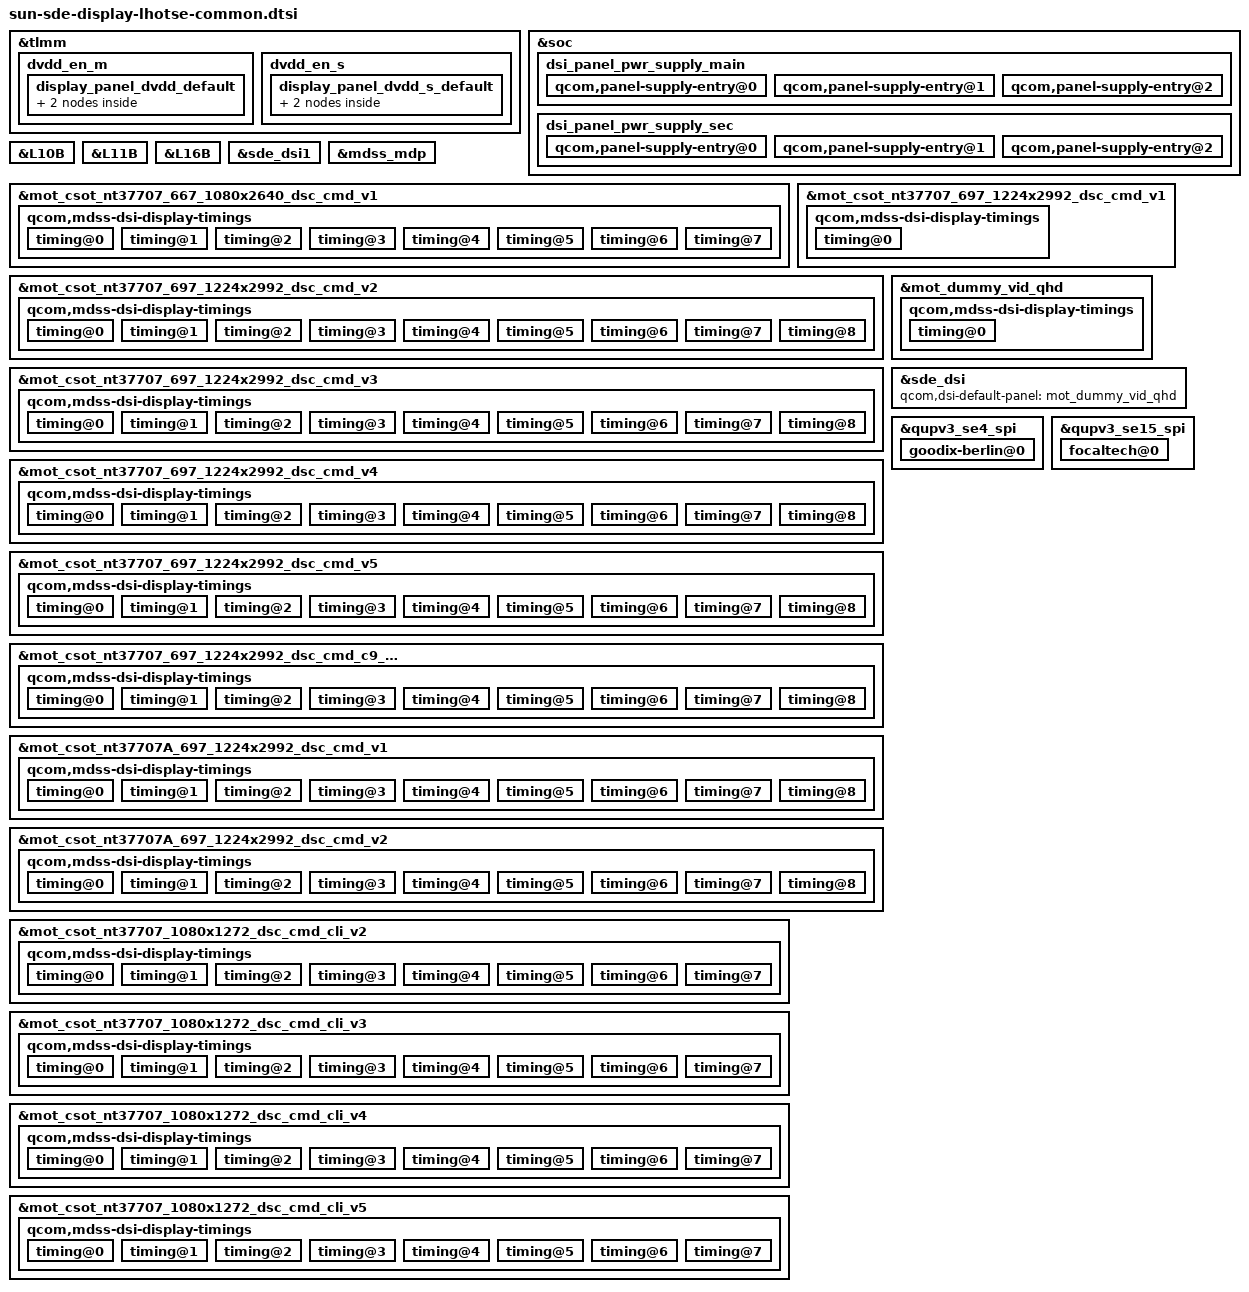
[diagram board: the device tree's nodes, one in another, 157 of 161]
// SPDX-License-Identifier: BSD-3-Clause
/*
 * Copyright (c) 2023-2024, Qualcomm Innovation Center, Inc. All rights reserved.
 */

#include "sun-sde-display.dtsi"
#include "dsi-panel-mot-dummy-qhd-video.dtsi"
#include "dsi-panel-mot-csot-nt37707-667-1080x2640-dsc-cmd-common_v1.dtsi"
#include "dsi-panel-mot-csot-nt37707-697-1224x2992-dsc-cmd-common_v1.dtsi"
#include "dsi-panel-mot-csot-nt37707-697-1224x2992-dsc-cmd-common_v2.dtsi"
#include "dsi-panel-mot-csot-nt37707-697-1224x2992-dsc-cmd-common_v3.dtsi"
#include "dsi-panel-mot-csot-nt37707-697-1224x2992-dsc-cmd-common_v4.dtsi"
#include "dsi-panel-mot-csot-nt37707-697-1224x2992-dsc-cmd-common_v5.dtsi"
#include "dsi-panel-mot-csot-nt37707-697-1224x2992-dsc-cmd-common_c9_v1.dtsi"
#include "dsi-panel-mot-csot-nt37707A-697-1224x2992-dsc-cmd-common_v1.dtsi"
#include "dsi-panel-mot-csot-nt37707A-697-1224x2992-dsc-cmd-common_v2.dtsi"
#include "dsi-panel-mot-csot-nt37707-1080x1272-dsc-cmd-common-cli_v2.dtsi"
#include "dsi-panel-mot-csot-nt37707-1080x1272-dsc-cmd-common-cli_v3.dtsi"
#include "dsi-panel-mot-csot-nt37707-1080x1272-dsc-cmd-common-cli_v4.dtsi"
#include "dsi-panel-mot-csot-nt37707-1080x1272-dsc-cmd-common-cli_v5.dtsi"

&tlmm {
	dvdd_en_m {
		display_panel_dvdd_default: display_panel_dvdd_default { //dvdd 1.23V
			mux {
				pins = "gpio111";
				function = "gpio";
			};

			config {
				pins = "gpio111";
				drive-strength = <2>;   /* 2 mA */
				bias-disable = <0>;   /* no pull */
				output-enable;
			};
		};
	};
	dvdd_en_s {
		display_panel_dvdd_s_default: display_panel_dvdd_s_default {
			mux {
				pins = "gpio60";
				function = "gpio";
			};

			config {
				pins = "gpio60";
				drive-strength = <2>;   /* 2 mA */
				bias-disable = <0>;   /* no pull */
				output-enable;
			};
		};
	};
};

&soc {
	dsi_panel_pwr_supply_main: dsi_panel_pwr_supply_main {
		#address-cells = <1>;
		#size-cells = <0>;

	qcom,panel-supply-entry@0 {
		reg = <0>;
		qcom,supply-name = "vddio";
		qcom,supply-min-voltage = <1800000>;
		qcom,supply-max-voltage = <1800000>;
		qcom,supply-enable-load = <300000>;
		qcom,supply-disable-load = <100>;
		qcom,supply-pre-on-sleep = <0>;
		qcom,supply-post-on-sleep = <1>;
		qcom,supply-pre-off-sleep = <0>;
		qcom,supply-post-off-sleep = <0>;
        };
	qcom,panel-supply-entry@1 {
		reg = <1>;
		qcom,supply-name = "vdd";
		qcom,supply-min-voltage = <1200000>;
		qcom,supply-max-voltage = <1250000>;
		qcom,supply-enable-load = <300000>;
		qcom,supply-disable-load = <100>;
		qcom,supply-pre-on-sleep = <0>;
		qcom,supply-post-on-sleep = <1>;
		qcom,supply-pre-off-sleep = <0>;
		qcom,supply-post-off-sleep = <1>;
        };

        qcom,panel-supply-entry@2 {
		reg = <2>;
		qcom,supply-name = "vci";
		qcom,supply-min-voltage = <3000000>;
		qcom,supply-max-voltage = <3000000>;
		qcom,supply-enable-load = <300000>;
		qcom,supply-disable-load = <0>;
		qcom,supply-pre-on-sleep = <0>;
		qcom,supply-post-on-sleep = <0>;
		qcom,supply-pre-off-sleep = <0>;
		qcom,supply-post-off-sleep = <1>;
        };
	};
	dsi_panel_pwr_supply_sec: dsi_panel_pwr_supply_sec {
		#address-cells = <1>;
		#size-cells = <0>;

	qcom,panel-supply-entry@0 {
		reg = <0>;
		qcom,supply-name = "vddio";
		qcom,supply-min-voltage = <1800000>;
		qcom,supply-max-voltage = <1800000>;
		qcom,supply-enable-load = <300000>;
		qcom,supply-disable-load = <100>;
		qcom,supply-pre-on-sleep = <0>;
		qcom,supply-post-on-sleep = <1>;
		qcom,supply-pre-off-sleep = <0>;
		qcom,supply-post-off-sleep = <0>;
        };
	qcom,panel-supply-entry@1 {
		reg = <1>;
		qcom,supply-name = "vdd";
		qcom,supply-min-voltage = <1250000>;
		qcom,supply-max-voltage = <1250000>;
		qcom,supply-enable-load = <300000>;
		qcom,supply-disable-load = <100>;
		qcom,supply-pre-on-sleep = <0>;
		qcom,supply-post-on-sleep = <1>;
		qcom,supply-pre-off-sleep = <0>;
		qcom,supply-post-off-sleep = <1>;
        };

        qcom,panel-supply-entry@2 {
		reg = <2>;
		qcom,supply-name = "vci";
		qcom,supply-min-voltage = <3000000>;
		qcom,supply-max-voltage = <3000000>;
		qcom,supply-enable-load = <300000>;
		qcom,supply-disable-load = <0>;
		qcom,supply-pre-on-sleep = <0>;
		qcom,supply-post-on-sleep = <0>;
		qcom,supply-pre-off-sleep = <0>;
		qcom,supply-post-off-sleep = <1>;
        };
	};
};

&L10B {
       regulator-min-microvolt = <1800000>;
       regulator-max-microvolt = <1800000>;
       qcom,init-voltage = <1800000>;
};

&L11B {
       regulator-min-microvolt = <1250000>;
       regulator-max-microvolt = <1250000>;
       qcom,init-voltage = <1250000>;
};

&L16B {
       regulator-min-microvolt = <3000000>;
       regulator-max-microvolt = <3000000>;
       qcom,init-voltage = <3000000>;
};

&sde_dsi1 {
	pinctrl-0 = <&sde_dsi1_active &sde_te1_active>;
	pinctrl-1 = <&sde_dsi1_active &sde_te1_active>;
	pinctrl-2 = <&sde_dsi1_suspend &sde_te1_suspend>;
	vddio-supply = <&L10B>;
	vdd-supply = <&L11B>;
	vci-supply = <&L16B>;
};

&mdss_mdp {
	connectors = <&sde_dsi &sde_dsi1 &smmu_sde_unsec &smmu_sde_sec &sde_wb1 &sde_wb2 &sde_cesta>;
};

&mot_csot_nt37707_667_1080x2640_dsc_cmd_v1 {
	qcom,dsi-select-clocks = "pll_byte_clk0", "pll_dsi_clk0";
	qcom,panel-supply-entries = <&dsi_panel_pwr_supply_main>;
	qcom,mdss-dsi-no-panel-on-read-support;
	qcom,mdss-dsi-bl-pmic-control-type = "bl_ctrl_dcs";
	qcom,mdss-dsi-bl-min-level = <420>;
	qcom,mdss-dsi-bl-max-level = <15584>;
	qcom,mdss-dsi-bl-default-level = <8190>;
	qcom,mdss-brightness-max-level = <15584>;
	qcom,platform-reset-gpio = <&tlmm 98 0>;
	qcom,platform-vdd-enable-gpio = <&tlmm 111 0>;
	qcom,bl-dsc-cmd-state = "dsi_hs_mode";
	qcom,mdss-dsi-bl-inverted-dbv;
	qcom,mdss-dsi-bl-is-exponent;

	qcom,mdss-dsi-panel-status-check-mode = "reg_read";
	qcom,mdss-dsi-panel-status-command = [06 01 00 01 00 00 01 0a];
	qcom,mdss-dsi-panel-status-command-state = "dsi_lp_mode";
	qcom,mdss-dsi-panel-status-value = <0x9c>;
	qcom,mdss-dsi-panel-status-read-length = <1>;
	qcom,esd-check-enabled;
	qcom,cellid-read-enabled;
	qcom,mdss-dsi-panel-cellid-read-length = <36>;
	qcom,mdss-dsi-panel-cellid-offset = <13>;
	qcom,mdss-dsi-panel-cellid-command = [
		06 01 00 01 00 00 01 AC];

	qcom,mdss-dsi-panel-hdr-enabled;
	qcom,mdss-dsi-panel-hdr-color-primaries = <15600 16450 34000
	        16000 13250 34500 7500 3000>;
	qcom,mdss-dsi-panel-peak-brightness = <15000000>;
	qcom,mdss-dsi-panel-blackness-level = <1>;

	qcom,apl-enabled;
	qcom,mdss-dsi-panel-APL-THRESHOLD-BL = <15102>;
	qcom,mdss-dsi-panel-APL-FUNC-ID = <0>;
	qcom,mdss-dsi-panel-apl-on-command = [
		39 00 00 00 00 00 03 5F 00 01];
	qcom,mdss-dsi-panel-apl-off-command = [
		39 00 00 00 00 00 03 5F 00 00];
	qcom,is_legacy_panel;
	//qcom,ulps-enabled;
	qcom,mdss-dsi-display-timings {
		timing@0 { //120
			qcom,framerate-group-no-duplicated;
			qcom,framerate-group-120hz-based;
			qcom,partial-update-enabled = "single_roi";
			qcom,panel-roi-alignment = <1080 120 1080 120 1080 120>;
			//qcom,mdss-dsi-panel-clockrate = <800000000>;
			qcom,display-topology = <1 1 1>;
			qcom,default-topology-index = <0>;
			qcom,mdss-dsi-panel-phy-timings = [00 1B 07 06 16 15 07
							07 07 02 04 00 17 0C];
		};
		timing@1 { //90
			qcom,framerate-group-no-duplicated;
			qcom,framerate-group-90hz-based;
			qcom,partial-update-enabled = "single_roi";
			qcom,panel-roi-alignment = <1080 120 1080 120 1080 120>;
			//qcom,mdss-dsi-panel-clockrate = <600000000>;
			qcom,display-topology = <1 1 1>;
			qcom,default-topology-index = <0>;
			qcom,mdss-dsi-panel-phy-timings = [00 16 05 05 14 1F 06
							05 06 02 04 00 13 0A];
		};
		timing@2 { //60
			qcom,framerate-group-no-duplicated;
			qcom,framerate-group-120hz-based;
			qcom,partial-update-enabled = "single_roi";
			qcom,panel-roi-alignment = <1080 120 1080 120 1080 120>;
			qcom,mdss-dsi-panel-clockrate = <500000000>;
			qcom,display-topology = <1 1 1>;
			qcom,default-topology-index = <0>;
			qcom,mdss-dsi-panel-phy-timings = [00 1B 07 06 16 21 07
							07 07 02 04 00 17 0C];
		};
		timing@3 { //30
			qcom,framerate-group-no-duplicated;
			qcom,framerate-group-120hz-based;
			qcom,framerate-group-90hz-based;
			qcom,partial-update-enabled = "single_roi";
			qcom,panel-roi-alignment = <1080 120 1080 120 1080 120>;
			//qcom,mdss-dsi-panel-clockrate = <800000000>;
			qcom,display-topology = <1 1 1>;
			qcom,default-topology-index = <0>;
			qcom,mdss-dsi-panel-phy-timings = [00 1B 07 06 16 21 07
							07 07 02 04 00 17 0C];
		};
		timing@4 { //24
			qcom,framerate-group-no-duplicated;
			qcom,framerate-group-120hz-based;
			qcom,partial-update-enabled = "single_roi";
			qcom,panel-roi-alignment = <1080 120 1080 120 1080 120>;
			//qcom,mdss-dsi-panel-clockrate = <800000000>;
			qcom,display-topology = <1 1 1>;
			qcom,default-topology-index = <0>;
			qcom,mdss-dsi-panel-phy-timings = [00 1B 07 06 16 15 07
							07 07 02 04 00 17 0C];
		};
		timing@5 { //10 independent
			qcom,framerate-group-special-idle-10hz;
			qcom,partial-update-enabled = "single_roi";
			qcom,panel-roi-alignment = <1080 120 1080 120 1080 120>;
			//qcom,mdss-dsi-panel-clockrate = <809000000>;
			qcom,display-topology = <1 1 1>;
			qcom,default-topology-index = <0>;
			qcom,mdss-dsi-panel-phy-timings = [00 1B 07 07 17 15 07
							07 08 02 04 00 18 0C];
		};
		timing@6 { //1 independent
			qcom,framerate-group-special-idle-1hz;
			qcom,partial-update-enabled = "single_roi";
			qcom,panel-roi-alignment = <1080 120 1080 120 1080 120>;
			//qcom,mdss-dsi-panel-clockrate = <809000000>;
			qcom,display-topology = <1 1 1>;
			qcom,default-topology-index = <0>;
			qcom,mdss-dsi-panel-phy-timings = [00 1B 07 07 17 15 07
							07 08 02 04 00 18 0C];
		};
		timing@7 { //165
			qcom,framerate-group-no-duplicated;
			qcom,partial-update-enabled = "single_roi";
			qcom,panel-roi-alignment = <1080 120 1080 120 1080 120>;
			//qcom,mdss-dsi-panel-clockrate = <1100000000>;
			qcom,display-topology = <1 1 1>;
			qcom,default-topology-index = <0>;
			qcom,mdss-dsi-panel-phy-timings = [00 24 0A 0A 1A 19 09
							0A 09 02 04 00 1E 0F];
		};
	};
};

&mot_csot_nt37707_697_1224x2992_dsc_cmd_v1 {
	qcom,dsi-select-clocks = "pll_byte_clk0", "pll_dsi_clk0";
	qcom,panel-supply-entries = <&dsi_panel_pwr_supply_main>;
	qcom,mdss-dsi-no-panel-on-read-support;
	qcom,mdss-dsi-bl-pmic-control-type = "bl_ctrl_dcs";
	qcom,mdss-dsi-bl-min-level = <420>;
	qcom,mdss-dsi-bl-max-level = <15584>;
	qcom,mdss-dsi-bl-default-level = <8190>;
	qcom,mdss-brightness-max-level = <15584>;
	qcom,platform-reset-gpio = <&tlmm 98 0>;
	qcom,platform-vdd-enable-gpio = <&tlmm 111 0>;
	qcom,bl-dsc-cmd-state = "dsi_hs_mode";
	qcom,mdss-dsi-bl-inverted-dbv;
	qcom,mdss-dsi-bl-is-exponent;

	qcom,mdss-dsi-panel-status-check-mode = "reg_read";
	qcom,mdss-dsi-panel-status-command = [06 01 00 01 00 00 01 0a];
	qcom,mdss-dsi-panel-status-command-state = "dsi_lp_mode";
	qcom,mdss-dsi-panel-status-value = <0x9c>;
	qcom,mdss-dsi-panel-status-read-length = <1>;
	qcom,esd-check-enabled;
	qcom,cellid-read-enabled;
	qcom,mdss-dsi-panel-cellid-read-length = <36>;
	qcom,mdss-dsi-panel-cellid-offset = <13>;
	qcom,mdss-dsi-panel-cellid-command = [
		06 01 00 01 00 00 01 AC];

	qcom,mdss-dsi-panel-hdr-enabled;
	qcom,mdss-dsi-panel-hdr-color-primaries = <15600 16450 34000
	        16000 13250 34500 7500 3000>;
	qcom,mdss-dsi-panel-peak-brightness = <20000000>;
	qcom,mdss-dsi-panel-blackness-level = <1>;

	//qcom,apl-enabled;
	qcom,mdss-dsi-panel-APL-THRESHOLD-BL = <15102>;
	qcom,mdss-dsi-panel-APL-FUNC-ID = <0>;
	qcom,mdss-dsi-panel-apl-on-command = [
		39 00 00 00 00 00 03 5F 00 01];
	qcom,mdss-dsi-panel-apl-off-command = [
		39 00 00 00 00 00 03 5F 00 00];
	qcom,is_legacy_panel;
	//qcom,ulps-enabled;
	qcom,mdss-dsi-display-timings {
		timing@0 { //120
			qcom,framerate-group-no-duplicated;
			qcom,framerate-group-120hz-based;
			qcom,partial-update-enabled = "single_roi";
			qcom,panel-roi-alignment = <1224 160 1224 160 1224 160>;
			//qcom,mdss-dsi-panel-clockrate = <800000000>;
			qcom,display-topology = <2 2 1>;
			qcom,default-topology-index = <0>;
			qcom,mdss-dsi-panel-phy-timings = [00 2B 0C 0C 1C 1A 0C
							0C 0B 02 04 00 24 10];
		};
		/*timing@1 { //90
			qcom,framerate-group-no-duplicated;
			qcom,framerate-group-90hz-based;
			qcom,partial-update-enabled = "single_roi";
			qcom,panel-roi-alignment = <1224 120 1224 120 1224 120>;
			//qcom,mdss-dsi-panel-clockrate = <600000000>;
			qcom,display-topology = <2 2 1>;
			qcom,default-topology-index = <0>;
			qcom,mdss-dsi-panel-phy-timings = [00 2B 0C 0C 1C 1A 0C
							0C 0B 02 04 00 24 10];
		};
		timing@2 { //165 independent
			qcom,framerate-group-special-idle-1hz;
			qcom,partial-update-enabled = "single_roi";
			qcom,panel-roi-alignment = <1224 120 1224 120 1224 120>;
			//qcom,mdss-dsi-panel-clockrate = <809000000>;
			qcom,display-topology = <2 2 1>;
			qcom,default-topology-index = <0>;
			qcom,mdss-dsi-panel-phy-timings = [00 2B 0C 0C 1C 1A 0C
							0C 0B 02 04 00 24 10];
		};*/
	};
};

&mot_csot_nt37707_697_1224x2992_dsc_cmd_v2 {
	qcom,dsi-select-clocks = "pll_byte_clk0", "pll_dsi_clk0";
	qcom,panel-supply-entries = <&dsi_panel_pwr_supply_main>;
	qcom,mdss-dsi-no-panel-on-read-support;
	qcom,mdss-dsi-bl-pmic-control-type = "bl_ctrl_dcs";
	qcom,mdss-dsi-bl-min-level = <420>;
	qcom,mdss-dsi-bl-max-level = <15584>;
	qcom,mdss-dsi-bl-default-level = <8190>;
	qcom,mdss-brightness-max-level = <15584>;
	qcom,platform-reset-gpio = <&tlmm 98 0>;
	qcom,platform-vdd-enable-gpio = <&tlmm 111 0>;
	qcom,bl-dsc-cmd-state = "dsi_hs_mode";
	qcom,mdss-dsi-bl-inverted-dbv;
	qcom,mdss-dsi-bl-is-exponent;

	qcom,mdss-dsi-panel-status-check-mode = "reg_read";
	qcom,mdss-dsi-panel-status-command = [06 01 00 01 00 00 01 0a];
	qcom,mdss-dsi-panel-status-command-state = "dsi_lp_mode";
	qcom,mdss-dsi-panel-status-value = <0x9c>;
	qcom,mdss-dsi-panel-status-read-length = <1>;
	qcom,esd-check-enabled;
	qcom,cellid-read-enabled;
	qcom,mdss-dsi-panel-cellid-read-length = <36>;
	qcom,mdss-dsi-panel-cellid-offset = <13>;
	qcom,mdss-dsi-panel-cellid-command = [
		06 01 00 01 00 00 01 AC];

	qcom,mdss-dsi-panel-hdr-enabled;
	qcom,mdss-dsi-panel-hdr-color-primaries = <15600 16450 34000
	        16000 13250 34500 7500 3000>;
	qcom,mdss-dsi-panel-peak-brightness = <20000000>;
	qcom,mdss-dsi-panel-blackness-level = <1>;

	//qcom,apl-enabled;
	qcom,mdss-dsi-panel-APL-THRESHOLD-BL = <15102>;
	qcom,mdss-dsi-panel-APL-FUNC-ID = <0>;
	qcom,mdss-dsi-panel-apl-on-command = [
		39 00 00 00 00 00 03 5F 00 01];
	qcom,mdss-dsi-panel-apl-off-command = [
		39 00 00 00 00 00 03 5F 00 00];
	qcom,partition-refreshrate-enabled;
	qcom,mdss-dsi-panel-boundaryLine-reg-count = <6>;
	//qcom,ulps-enabled;
	qcom,is_legacy_panel;
	qcom,mdss-dsi-hbm-off-command = [
		39 00 00 40 00 00 03 5F 00 00
		39 00 00 00 00 00 03 51 2C 50
	];
	qcom,mdss-dsi-hbm-off-command-state = "dsi_hs_mode";
	qcom,mdss-dsi-hbm-on-command = [
		39 00 00 40 00 00 03 5F 00 01
		39 00 00 00 00 00 03 51 3F FC
	];
	qcom,mdss-dsi-hbm-on-command-state = "dsi_hs_mode";
	qcom,mdss-dsi-display-timings {
		timing@0 { //120
			qcom,framerate-group-no-duplicated;
			qcom,framerate-group-120hz-based;
			qcom,partial-update-enabled = "single_roi";
			qcom,panel-roi-alignment = <1224 160 1224 160 1224 160>;
			//qcom,mdss-dsi-panel-clockrate = <1036000000>;
			qcom,display-topology = <2 2 1>;
			qcom,default-topology-index = <0>;
			qcom,mdss-dsi-panel-phy-timings = [00 22 09 09 19 18 09
							09 09 02 04 00 1D 0E];
		};
		timing@1 { //90
			qcom,framerate-group-no-duplicated;
			qcom,framerate-group-90hz-based;
			qcom,partial-update-enabled = "single_roi";
			qcom,panel-roi-alignment = <1224 160 1224 160 1224 160>;
			//qcom,mdss-dsi-panel-clockrate = <777000000>;
			qcom,display-topology = <2 2 1>;
			qcom,default-topology-index = <0>;
			qcom,mdss-dsi-panel-phy-timings = [00 1B 07 06 16 21 07
							07 07 02 04 00 17 0C];
		};
		timing@2 { //60
			qcom,framerate-group-no-duplicated;
			qcom,framerate-group-120hz-based;
			qcom,partial-update-enabled = "single_roi";
			qcom,panel-roi-alignment = <1224 160 1224 160 1224 160>;
			//qcom,mdss-dsi-panel-clockrate = <518000000>;
			qcom,display-topology = <2 2 1>;
			qcom,default-topology-index = <0>;
			qcom,mdss-dsi-panel-phy-timings = [00 13 05 04 13 1E 05
							05 06 02 04 00 12 0A];
		};
		timing@3 { //30
			qcom,framerate-group-no-duplicated;
			qcom,framerate-group-120hz-based;
			qcom,partial-update-enabled = "single_roi";
			qcom,panel-roi-alignment = <1224 160 1224 160 1224 160>;
			//qcom,mdss-dsi-panel-clockrate = <1036000000>;
			qcom,display-topology = <2 2 1>;
			qcom,default-topology-index = <0>;
			qcom,mdss-dsi-panel-phy-timings = [00 22 09 09 19 18 09
							09 09 02 04 00 1D 0E];
		};
		timing@4 { //24
			qcom,framerate-group-no-duplicated;
			qcom,framerate-group-120hz-based;
			qcom,partial-update-enabled = "single_roi";
			qcom,panel-roi-alignment = <1224 160 1224 160 1224 160>;
			//qcom,mdss-dsi-panel-clockrate = <1036000000>;
			qcom,display-topology = <2 2 1>;
			qcom,default-topology-index = <0>;
			qcom,mdss-dsi-panel-phy-timings = [00 22 09 09 19 18 09
							09 09 02 04 00 1D 0E];
		};
		timing@5 { //10 independent
			qcom,framerate-group-special-idle-10hz;
			qcom,partial-update-enabled = "single_roi";
			qcom,panel-roi-alignment = <1224 160 1224 160 1224 160>;
			//qcom,mdss-dsi-panel-clockrate = <1036000000>;
			qcom,display-topology = <2 2 1>;
			qcom,default-topology-index = <0>;
			qcom,mdss-dsi-panel-phy-timings = [00 22 09 09 19 18 09
							09 09 02 04 00 1D 0E];
		};
		timing@6 { //1 independent
			qcom,framerate-group-special-idle-1hz;
			qcom,partial-update-enabled = "single_roi";
			qcom,panel-roi-alignment = <1224 160 1224 160 1224 160>;
			//qcom,mdss-dsi-panel-clockrate = <1036000000>;
			qcom,display-topology = <2 2 1>;
			qcom,default-topology-index = <0>;
			qcom,mdss-dsi-panel-phy-timings = [00 22 09 09 19 18 09
							09 09 02 04 00 1D 0E];
		};
		timing@7 { //165
			qcom,framerate-group-no-duplicated;
			qcom,partial-update-enabled = "single_roi";
			qcom,panel-roi-alignment = <1224 160 1224 160 1224 160>;
			//qcom,mdss-dsi-panel-clockrate = <1424000000>;
			qcom,display-topology = <2 2 1>;
			qcom,default-topology-index = <0>;
			qcom,mdss-dsi-panel-phy-timings = [00 2E 0C 0C 1D 1B 0C
							0D 0B 02 04 00 25 11];
		};
		/*timing@8 { //10-120-10 independent
			qcom,framerate-group-partition-refreshrate;
			qcom,partial-update-enabled = "single_roi";
			qcom,panel-roi-alignment = <1224 160 1224 160 1224 160>;
			//qcom,mdss-dsi-panel-clockrate = <1036000000>;
			qcom,display-topology = <2 2 1>;
			qcom,default-topology-index = <0>;
			qcom,mdss-dsi-panel-phy-timings = [00 22 09 09 19 18 09
							09 09 02 04 00 1D 0E];
		};*/
		timing@8 { //10-60-10 independent
			qcom,framerate-group-partition-refreshrate;
			qcom,partial-update-enabled = "single_roi";
			qcom,panel-roi-alignment = <1224 160 1224 160 1224 160>;
			qcom,mdss-dsi-panel-clockrate = <1036000000>;
			qcom,display-topology = <2 2 1>;
			qcom,default-topology-index = <0>;
			qcom,mdss-dsi-panel-phy-timings = [00 22 09 09 19 18 09
							09 09 02 04 00 1D 0E];
		};
	};
};

&mot_csot_nt37707_697_1224x2992_dsc_cmd_v3 {
	qcom,dsi-select-clocks = "pll_byte_clk0", "pll_dsi_clk0";
	qcom,panel-supply-entries = <&dsi_panel_pwr_supply_main>;
	qcom,mdss-dsi-no-panel-on-read-support;
	qcom,mdss-dsi-bl-pmic-control-type = "bl_ctrl_dcs";
	qcom,mdss-dsi-bl-min-level = <420>;
	qcom,mdss-dsi-bl-max-level = <15584>;
	qcom,mdss-dsi-bl-default-level = <8190>;
	qcom,mdss-brightness-max-level = <15584>;
	qcom,platform-reset-gpio = <&tlmm 98 0>;
	qcom,platform-vdd-enable-gpio = <&tlmm 111 0>;
	qcom,bl-dsc-cmd-state = "dsi_hs_mode";
	qcom,mdss-dsi-bl-inverted-dbv;
	qcom,mdss-dsi-bl-is-exponent;

	qcom,mdss-dsi-panel-status-check-mode = "reg_read";
	qcom,mdss-dsi-panel-status-command = [06 01 00 01 00 00 01 0a];
	qcom,mdss-dsi-panel-status-command-state = "dsi_lp_mode";
	qcom,mdss-dsi-panel-status-value = <0x9c>;
	qcom,mdss-dsi-panel-status-read-length = <1>;
	qcom,esd-check-enabled;
	qcom,cellid-read-enabled;
	qcom,mdss-dsi-panel-cellid-read-length = <36>;
	qcom,mdss-dsi-panel-cellid-offset = <13>;
	qcom,mdss-dsi-panel-cellid-command = [
		06 01 00 01 00 00 01 AC];

	qcom,mdss-dsi-panel-hdr-enabled;
	qcom,mdss-dsi-panel-hdr-color-primaries = <15600 16450 34000
	        16000 13250 34500 7500 3000>;
	qcom,mdss-dsi-panel-peak-brightness = <20000000>;
	qcom,mdss-dsi-panel-blackness-level = <1>;
	qcom,is_legacy_panel;
	//qcom,apl-enabled;
	qcom,mdss-dsi-panel-APL-THRESHOLD-BL = <15102>;
	qcom,mdss-dsi-panel-APL-FUNC-ID = <0>;
	qcom,mdss-dsi-panel-apl-on-command = [
		39 00 00 00 00 00 03 5F 00 01];
	qcom,mdss-dsi-panel-apl-off-command = [
		39 00 00 00 00 00 03 5F 00 00];
	qcom,partition-refreshrate-enabled;
	qcom,mdss-dsi-panel-boundaryLine-reg-count = <6>;
	//qcom,ulps-enabled;
	qcom,mdss-dsi-hbm-off-command = [
		39 00 00 40 00 00 03 5F 00 00
		39 00 00 00 00 00 03 51 2C 50
	];
	qcom,mdss-dsi-hbm-off-command-state = "dsi_hs_mode";
	qcom,mdss-dsi-hbm-on-command = [
		39 00 00 40 00 00 03 5F 00 01
		39 00 00 00 00 00 03 51 3F FC
	];
	qcom,mdss-dsi-hbm-on-command-state = "dsi_hs_mode";
	qcom,mdss-dsi-display-timings {
		timing@0 { //120
			qcom,framerate-group-no-duplicated;
			qcom,framerate-group-120hz-based;
			qcom,partial-update-enabled = "single_roi";
			qcom,panel-roi-alignment = <1224 160 1224 160 1224 160>;
			qcom,mdss-dsi-panel-clockrate = <1036000000>;
			qcom,display-topology = <2 2 1>;
			qcom,default-topology-index = <0>;
			qcom,mdss-dsi-panel-phy-timings = [00 22 09 09 19 18 09
							09 09 02 04 00 1D 0E];
		};
		timing@1 { //90
			qcom,framerate-group-no-duplicated;
			qcom,framerate-group-90hz-based;
			qcom,partial-update-enabled = "single_roi";
			qcom,panel-roi-alignment = <1224 160 1224 160 1224 160>;
			qcom,mdss-dsi-panel-clockrate = <777000000>;
			qcom,display-topology = <2 2 1>;
			qcom,default-topology-index = <0>;
			qcom,mdss-dsi-panel-phy-timings = [00 1B 07 06 16 21 07
							07 07 02 04 00 17 0C];
		};
		timing@2 { //60
			qcom,framerate-group-no-duplicated;
			qcom,framerate-group-120hz-based;
			qcom,partial-update-enabled = "single_roi";
			qcom,panel-roi-alignment = <1224 160 1224 160 1224 160>;
			qcom,mdss-dsi-panel-clockrate = <518000000>;
			qcom,display-topology = <2 2 1>;
			qcom,default-topology-index = <0>;
			qcom,mdss-dsi-panel-phy-timings = [00 13 05 04 13 1E 05
							05 06 02 04 00 12 0A];
		};
		timing@3 { //30
			qcom,framerate-group-no-duplicated;
			qcom,framerate-group-120hz-based;
			qcom,partial-update-enabled = "single_roi";
			qcom,panel-roi-alignment = <1224 160 1224 160 1224 160>;
			qcom,mdss-dsi-panel-clockrate = <1036000000>;
			qcom,display-topology = <2 2 1>;
			qcom,default-topology-index = <0>;
			qcom,mdss-dsi-panel-phy-timings = [00 22 09 09 19 18 09
							09 09 02 04 00 1D 0E];
		};
		timing@4 { //24
			qcom,framerate-group-no-duplicated;
			qcom,framerate-group-120hz-based;
			qcom,partial-update-enabled = "single_roi";
			qcom,panel-roi-alignment = <1224 160 1224 160 1224 160>;
			qcom,mdss-dsi-panel-clockrate = <1036000000>;
			qcom,display-topology = <2 2 1>;
			qcom,default-topology-index = <0>;
			qcom,mdss-dsi-panel-phy-timings = [00 22 09 09 19 18 09
							09 09 02 04 00 1D 0E];
		};
		timing@5 { //10 independent
			qcom,framerate-group-special-idle-10hz;
			qcom,partial-update-enabled = "single_roi";
			qcom,panel-roi-alignment = <1224 160 1224 160 1224 160>;
			qcom,mdss-dsi-panel-clockrate = <1036000000>;
			qcom,display-topology = <2 2 1>;
			qcom,default-topology-index = <0>;
			qcom,mdss-dsi-panel-phy-timings = [00 22 09 09 19 18 09
							09 09 02 04 00 1D 0E];
		};
		timing@6 { //1 independent
			qcom,framerate-group-special-idle-1hz;
			qcom,partial-update-enabled = "single_roi";
			qcom,panel-roi-alignment = <1224 160 1224 160 1224 160>;
			qcom,mdss-dsi-panel-clockrate = <1036000000>;
			qcom,display-topology = <2 2 1>;
			qcom,default-topology-index = <0>;
			qcom,mdss-dsi-panel-phy-timings = [00 22 09 09 19 18 09
							09 09 02 04 00 1D 0E];
		};
		timing@7 { //165
			qcom,framerate-group-no-duplicated;
			qcom,partial-update-enabled = "single_roi";
			qcom,panel-roi-alignment = <1224 160 1224 160 1224 160>;
			qcom,mdss-dsi-panel-clockrate = <1424000000>;
			qcom,display-topology = <2 2 1>;
			qcom,default-topology-index = <0>;
			qcom,mdss-dsi-panel-phy-timings = [00 2E 0C 0C 1D 1B 0C
							0D 0B 02 04 00 25 11];
		};
		/*timing@8 { //10-120-10 independent
			qcom,framerate-group-partition-refreshrate;
			qcom,partial-update-enabled = "single_roi";
			qcom,panel-roi-alignment = <1224 160 1224 160 1224 160>;
			qcom,mdss-dsi-panel-clockrate = <1036000000>;
			qcom,display-topology = <2 2 1>;
			qcom,default-topology-index = <0>;
			qcom,mdss-dsi-panel-phy-timings = [00 22 09 09 19 18 09
							09 09 02 04 00 1D 0E];
		};*/
		timing@8 { //10-60-10 independent
			qcom,framerate-group-partition-refreshrate;
			qcom,partial-update-enabled = "single_roi";
			qcom,panel-roi-alignment = <1224 160 1224 160 1224 160>;
			qcom,mdss-dsi-panel-clockrate = <1036000000>;
			qcom,display-topology = <2 2 1>;
			qcom,default-topology-index = <0>;
			qcom,mdss-dsi-panel-phy-timings = [00 22 09 09 19 18 09
							09 09 02 04 00 1D 0E];
		};
	};
};

&mot_csot_nt37707_697_1224x2992_dsc_cmd_v4 {
	qcom,dsi-select-clocks = "pll_byte_clk0", "pll_dsi_clk0";
	qcom,panel-supply-entries = <&dsi_panel_pwr_supply_main>;
	qcom,mdss-dsi-no-panel-on-read-support;
	qcom,mdss-dsi-bl-pmic-control-type = "bl_ctrl_dcs";
	qcom,mdss-dsi-bl-min-level = <420>;
	qcom,mdss-dsi-bl-max-level = <15584>;
	qcom,mdss-dsi-bl-default-level = <8190>;
	qcom,mdss-brightness-max-level = <15584>;
	qcom,platform-reset-gpio = <&tlmm 98 0>;
	qcom,platform-vdd-enable-gpio = <&tlmm 111 0>;
	qcom,bl-dsc-cmd-state = "dsi_hs_mode";
	qcom,mdss-dsi-bl-inverted-dbv;
	qcom,mdss-dsi-bl-is-exponent;

	qcom,mdss-dsi-panel-status-check-mode = "reg_read";
	qcom,mdss-dsi-panel-status-command = [06 01 00 01 00 00 01 0a];
	qcom,mdss-dsi-panel-status-command-state = "dsi_lp_mode";
	qcom,mdss-dsi-panel-status-value = <0x9c>;
	qcom,mdss-dsi-panel-status-read-length = <1>;
	qcom,esd-check-enabled;
	qcom,cellid-read-enabled;
	qcom,mdss-dsi-panel-cellid-read-length = <36>;
	qcom,mdss-dsi-panel-cellid-offset = <13>;
	qcom,mdss-dsi-panel-cellid-command = [
		06 01 00 01 00 00 01 AC];

	qcom,mdss-dsi-panel-hdr-enabled;
	qcom,mdss-dsi-panel-hdr-color-primaries = <15600 16450 34000
	        16000 13250 34500 7500 3000>;
	qcom,mdss-dsi-panel-peak-brightness = <20000000>;
	qcom,mdss-dsi-panel-blackness-level = <1>;
	qcom,is_legacy_panel;
	qcom,apl-enabled;
	qcom,mdss-dsi-panel-APL-THRESHOLD-BL = <15102>;
	qcom,mdss-dsi-panel-APL-FUNC-ID = <0>;
	qcom,mdss-dsi-panel-apl-on-command = [
		39 00 00 00 00 00 03 5F 00 01];
	qcom,mdss-dsi-panel-apl-off-command = [
		39 00 00 00 00 00 03 5F 00 00];
	qcom,partition-refreshrate-enabled;
	qcom,mdss-dsi-panel-boundaryLine-reg-count = <6>;
	//qcom,ulps-enabled;
	qcom,mdss-dsi-hbm-off-command = [
		39 00 00 40 00 00 03 5F 00 00
		39 00 00 00 00 00 03 51 2C 50
	];
	qcom,mdss-dsi-hbm-off-command-state = "dsi_hs_mode";
	qcom,mdss-dsi-hbm-on-command = [
		39 00 00 40 00 00 03 5F 00 01
		39 00 00 00 00 00 03 51 3F FC
	];
	qcom,mdss-dsi-hbm-on-command-state = "dsi_hs_mode";
	qcom,mdss-dsi-display-timings {
		timing@0 { //120
			qcom,framerate-group-no-duplicated;
			qcom,framerate-group-120hz-based;
			qcom,partial-update-enabled = "single_roi";
			qcom,panel-roi-alignment = <1224 160 1224 160 1224 160>;
			qcom,mdss-dsi-panel-clockrate = <1036000000>;
			qcom,display-topology = <2 2 1>;
			qcom,default-topology-index = <0>;
			qcom,mdss-dsi-panel-phy-timings = [00 22 09 09 19 18 09
							09 09 02 04 00 1D 0E];
		};
		timing@1 { //90
			qcom,framerate-group-no-duplicated;
			qcom,framerate-group-90hz-based;
			qcom,partial-update-enabled = "single_roi";
			qcom,panel-roi-alignment = <1224 160 1224 160 1224 160>;
			qcom,mdss-dsi-panel-clockrate = <777000000>;
			qcom,display-topology = <2 2 1>;
			qcom,default-topology-index = <0>;
			qcom,mdss-dsi-panel-phy-timings = [00 1B 07 06 16 21 07
							07 07 02 04 00 17 0C];
		};
		timing@2 { //60
			qcom,framerate-group-no-duplicated;
			qcom,framerate-group-120hz-based;
			qcom,partial-update-enabled = "single_roi";
			qcom,panel-roi-alignment = <1224 160 1224 160 1224 160>;
			qcom,mdss-dsi-panel-clockrate = <518000000>;
			qcom,display-topology = <2 2 1>;
			qcom,default-topology-index = <0>;
			qcom,mdss-dsi-panel-phy-timings = [00 13 05 04 13 1E 05
							05 06 02 04 00 12 0A];
		};
		timing@3 { //30
			qcom,framerate-group-no-duplicated;
			qcom,framerate-group-120hz-based;
			qcom,partial-update-enabled = "single_roi";
			qcom,panel-roi-alignment = <1224 160 1224 160 1224 160>;
			qcom,mdss-dsi-panel-clockrate = <1036000000>;
			qcom,display-topology = <2 2 1>;
			qcom,default-topology-index = <0>;
			qcom,mdss-dsi-panel-phy-timings = [00 22 09 09 19 18 09
							09 09 02 04 00 1D 0E];
		};
		timing@4 { //24
			qcom,framerate-group-no-duplicated;
			qcom,framerate-group-120hz-based;
			qcom,partial-update-enabled = "single_roi";
			qcom,panel-roi-alignment = <1224 160 1224 160 1224 160>;
			qcom,mdss-dsi-panel-clockrate = <1036000000>;
			qcom,display-topology = <2 2 1>;
			qcom,default-topology-index = <0>;
			qcom,mdss-dsi-panel-phy-timings = [00 22 09 09 19 18 09
							09 09 02 04 00 1D 0E];
		};
		timing@5 { //10 independent
			qcom,framerate-group-special-idle-10hz;
			qcom,partial-update-enabled = "single_roi";
			qcom,panel-roi-alignment = <1224 160 1224 160 1224 160>;
			qcom,mdss-dsi-panel-clockrate = <1036000000>;
			qcom,display-topology = <2 2 1>;
			qcom,default-topology-index = <0>;
			qcom,mdss-dsi-panel-phy-timings = [00 22 09 09 19 18 09
							09 09 02 04 00 1D 0E];
		};
		timing@6 { //1 independent
			qcom,framerate-group-special-idle-1hz;
			qcom,partial-update-enabled = "single_roi";
			qcom,panel-roi-alignment = <1224 160 1224 160 1224 160>;
			qcom,mdss-dsi-panel-clockrate = <1036000000>;
			qcom,display-topology = <2 2 1>;
			qcom,default-topology-index = <0>;
			qcom,mdss-dsi-panel-phy-timings = [00 22 09 09 19 18 09
							09 09 02 04 00 1D 0E];
		};
		timing@7 { //165
			qcom,framerate-group-no-duplicated;
			qcom,partial-update-enabled = "single_roi";
			qcom,panel-roi-alignment = <1224 160 1224 160 1224 160>;
			qcom,mdss-dsi-panel-clockrate = <1424000000>;
			qcom,display-topology = <2 2 1>;
			qcom,default-topology-index = <0>;
			qcom,mdss-dsi-panel-phy-timings = [00 2E 0C 0C 1D 1B 0C
							0D 0B 02 04 00 25 11];
		};
		/*timing@8 { //10-120-10 independent
			qcom,framerate-group-partition-refreshrate;
			qcom,partial-update-enabled = "single_roi";
			qcom,panel-roi-alignment = <1224 160 1224 160 1224 160>;
			qcom,mdss-dsi-panel-clockrate = <1036000000>;
			qcom,display-topology = <2 2 1>;
			qcom,default-topology-index = <0>;
			qcom,mdss-dsi-panel-phy-timings = [00 22 09 09 19 18 09
							09 09 02 04 00 1D 0E];
		};*/
		timing@8 { //10-60-10 independent
			qcom,framerate-group-partition-refreshrate;
			qcom,partial-update-enabled = "single_roi";
			qcom,panel-roi-alignment = <1224 160 1224 160 1224 160>;
			qcom,mdss-dsi-panel-clockrate = <1036000000>;
			qcom,display-topology = <2 2 1>;
			qcom,default-topology-index = <0>;
			qcom,mdss-dsi-panel-phy-timings = [00 22 09 09 19 18 09
							09 09 02 04 00 1D 0E];
		};
	};
};

&mot_csot_nt37707_697_1224x2992_dsc_cmd_v5 {
	qcom,dsi-select-clocks = "pll_byte_clk0", "pll_dsi_clk0";
	qcom,panel-supply-entries = <&dsi_panel_pwr_supply_main>;
	qcom,mdss-dsi-no-panel-on-read-support;
	qcom,mdss-dsi-bl-pmic-control-type = "bl_ctrl_dcs";
	qcom,mdss-dsi-bl-min-level = <420>;
	qcom,mdss-dsi-bl-max-level = <15584>;
	qcom,mdss-dsi-bl-default-level = <8190>;
	qcom,mdss-brightness-max-level = <15584>;
	qcom,platform-reset-gpio = <&tlmm 98 0>;
	qcom,platform-vdd-enable-gpio = <&tlmm 111 0>;
	qcom,bl-dsc-cmd-state = "dsi_hs_mode";
	qcom,mdss-dsi-bl-inverted-dbv;
	qcom,mdss-dsi-bl-is-exponent;

	qcom,mdss-dsi-panel-status-check-mode = "reg_read";
	qcom,mdss-dsi-panel-status-command = [06 01 00 01 00 00 01 0a];
	qcom,mdss-dsi-panel-status-command-state = "dsi_lp_mode";
	qcom,mdss-dsi-panel-status-value = <0x9c>;
	qcom,mdss-dsi-panel-status-read-length = <1>;
	qcom,esd-check-enabled;
	qcom,cellid-read-enabled;
	qcom,mdss-dsi-panel-cellid-read-length = <36>;
	qcom,mdss-dsi-panel-cellid-offset = <13>;
	qcom,mdss-dsi-panel-cellid-command = [
		06 01 00 01 00 00 01 AC];

	qcom,mdss-dsi-panel-hdr-enabled;
	qcom,mdss-dsi-panel-hdr-color-primaries = <15600 16450 34000
	        16000 13250 34500 7500 3000>;
	qcom,mdss-dsi-panel-peak-brightness = <20000000>;
	qcom,mdss-dsi-panel-blackness-level = <1>;
	qcom,is_legacy_panel;
	qcom,apl-enabled;
	qcom,mdss-dsi-panel-APL-THRESHOLD-BL = <15102>;
	qcom,mdss-dsi-panel-APL-FUNC-ID = <0>;
	qcom,mdss-dsi-panel-apl-on-command = [
		39 00 00 00 00 00 03 5F 00 01];
	qcom,mdss-dsi-panel-apl-off-command = [
		39 00 00 00 00 00 03 5F 00 00];
	qcom,partition-refreshrate-enabled;
	qcom,mdss-dsi-panel-boundaryLine-reg-count = <6>;
	//qcom,ulps-enabled;
	qcom,mdss-dsi-hbm-off-command = [
		39 00 00 40 00 00 03 5F 00 00
		39 00 00 00 00 00 03 51 2C 50
	];
	qcom,mdss-dsi-hbm-off-command-state = "dsi_hs_mode";
	qcom,mdss-dsi-hbm-on-command = [
		39 00 00 40 00 00 03 5F 00 01
		39 00 00 00 00 00 03 51 3F FC
	];
	qcom,mdss-dsi-hbm-on-command-state = "dsi_hs_mode";
	qcom,mdss-dsi-display-timings {
		timing@0 { //120
			qcom,framerate-group-no-duplicated;
			qcom,framerate-group-120hz-based;
			qcom,partial-update-enabled = "single_roi";
			qcom,panel-roi-alignment = <1224 160 1224 160 1224 160>;
			qcom,mdss-dsi-panel-clockrate = <1036000000>;
			qcom,display-topology = <2 2 1>;
			qcom,default-topology-index = <0>;
			qcom,mdss-dsi-panel-phy-timings = [00 22 09 09 19 18 09
							09 09 02 04 00 1D 0E];
		};
		timing@1 { //90
			qcom,framerate-group-no-duplicated;
			qcom,framerate-group-90hz-based;
			qcom,partial-update-enabled = "single_roi";
			qcom,panel-roi-alignment = <1224 160 1224 160 1224 160>;
			qcom,mdss-dsi-panel-clockrate = <777000000>;
			qcom,display-topology = <2 2 1>;
			qcom,default-topology-index = <0>;
			qcom,mdss-dsi-panel-phy-timings = [00 1B 07 06 16 21 07
							07 07 02 04 00 17 0C];
		};
		timing@2 { //60
			qcom,framerate-group-no-duplicated;
			qcom,framerate-group-120hz-based;
			qcom,partial-update-enabled = "single_roi";
			qcom,panel-roi-alignment = <1224 160 1224 160 1224 160>;
			qcom,mdss-dsi-panel-clockrate = <518000000>;
			qcom,display-topology = <2 2 1>;
			qcom,default-topology-index = <0>;
			qcom,mdss-dsi-panel-phy-timings = [00 13 05 04 13 1E 05
							05 06 02 04 00 12 0A];
		};
		timing@3 { //30
			qcom,framerate-group-no-duplicated;
			qcom,framerate-group-120hz-based;
			qcom,partial-update-enabled = "single_roi";
			qcom,panel-roi-alignment = <1224 160 1224 160 1224 160>;
			qcom,mdss-dsi-panel-clockrate = <1036000000>;
			qcom,display-topology = <2 2 1>;
			qcom,default-topology-index = <0>;
			qcom,mdss-dsi-panel-phy-timings = [00 22 09 09 19 18 09
							09 09 02 04 00 1D 0E];
		};
		timing@4 { //24
			qcom,framerate-group-no-duplicated;
			qcom,framerate-group-120hz-based;
			qcom,partial-update-enabled = "single_roi";
			qcom,panel-roi-alignment = <1224 160 1224 160 1224 160>;
			qcom,mdss-dsi-panel-clockrate = <1036000000>;
			qcom,display-topology = <2 2 1>;
			qcom,default-topology-index = <0>;
			qcom,mdss-dsi-panel-phy-timings = [00 22 09 09 19 18 09
							09 09 02 04 00 1D 0E];
		};
		timing@5 { //10 independent
			qcom,framerate-group-special-idle-10hz;
			qcom,partial-update-enabled = "single_roi";
			qcom,panel-roi-alignment = <1224 160 1224 160 1224 160>;
			qcom,mdss-dsi-panel-clockrate = <1036000000>;
			qcom,display-topology = <2 2 1>;
			qcom,default-topology-index = <0>;
			qcom,mdss-dsi-panel-phy-timings = [00 22 09 09 19 18 09
							09 09 02 04 00 1D 0E];
		};
		timing@6 { //1 independent
			qcom,framerate-group-special-idle-1hz;
			qcom,partial-update-enabled = "single_roi";
			qcom,panel-roi-alignment = <1224 160 1224 160 1224 160>;
			qcom,mdss-dsi-panel-clockrate = <1036000000>;
			qcom,display-topology = <2 2 1>;
			qcom,default-topology-index = <0>;
			qcom,mdss-dsi-panel-phy-timings = [00 22 09 09 19 18 09
							09 09 02 04 00 1D 0E];
		};
		timing@7 { //165
			qcom,framerate-group-no-duplicated;
			qcom,partial-update-enabled = "single_roi";
			qcom,panel-roi-alignment = <1224 160 1224 160 1224 160>;
			qcom,mdss-dsi-panel-clockrate = <1424000000>;
			qcom,display-topology = <2 2 1>;
			qcom,default-topology-index = <0>;
			qcom,mdss-dsi-panel-phy-timings = [00 2E 0C 0C 1D 1B 0C
							0D 0B 02 04 00 25 11];
		};
		/*timing@8 { //10-120-10 independent
			qcom,framerate-group-partition-refreshrate;
			qcom,partial-update-enabled = "single_roi";
			qcom,panel-roi-alignment = <1224 160 1224 160 1224 160>;
			qcom,mdss-dsi-panel-clockrate = <1036000000>;
			qcom,display-topology = <2 2 1>;
			qcom,default-topology-index = <0>;
			qcom,mdss-dsi-panel-phy-timings = [00 22 09 09 19 18 09
							09 09 02 04 00 1D 0E];
		};*/
		timing@8 { //10-60-10 independent
			qcom,framerate-group-partition-refreshrate;
			qcom,partial-update-enabled = "single_roi";
			qcom,panel-roi-alignment = <1224 160 1224 160 1224 160>;
			qcom,mdss-dsi-panel-clockrate = <1036000000>;
			qcom,display-topology = <2 2 1>;
			qcom,default-topology-index = <0>;
			qcom,mdss-dsi-panel-phy-timings = [00 22 09 09 19 18 09
							09 09 02 04 00 1D 0E];
		};
	};
};

&mot_csot_nt37707_697_1224x2992_dsc_cmd_c9_v1 {
	qcom,dsi-select-clocks = "pll_byte_clk0", "pll_dsi_clk0";
	qcom,panel-supply-entries = <&dsi_panel_pwr_supply_main>;
	qcom,mdss-dsi-no-panel-on-read-support;
	qcom,mdss-dsi-bl-pmic-control-type = "bl_ctrl_dcs";
	qcom,mdss-dsi-bl-min-level = <420>;
	qcom,mdss-dsi-bl-max-level = <15584>;
	qcom,mdss-dsi-bl-default-level = <8190>;
	qcom,mdss-brightness-max-level = <15584>;
	qcom,platform-reset-gpio = <&tlmm 98 0>;
	qcom,platform-vdd-enable-gpio = <&tlmm 111 0>;
	qcom,bl-dsc-cmd-state = "dsi_hs_mode";
	qcom,mdss-dsi-bl-inverted-dbv;
	qcom,mdss-dsi-bl-is-exponent;

	qcom,mdss-dsi-panel-status-check-mode = "reg_read";
	qcom,mdss-dsi-panel-status-command = [06 01 00 01 00 00 01 0a];
	qcom,mdss-dsi-panel-status-command-state = "dsi_lp_mode";
	qcom,mdss-dsi-panel-status-value = <0x9c>;
	qcom,mdss-dsi-panel-status-read-length = <1>;
	qcom,esd-check-enabled;
	qcom,cellid-read-enabled;
	qcom,mdss-dsi-panel-cellid-read-length = <36>;
	qcom,mdss-dsi-panel-cellid-offset = <13>;
	qcom,mdss-dsi-panel-cellid-command = [
		06 01 00 01 00 00 01 AC];

	qcom,mdss-dsi-panel-hdr-enabled;
	qcom,mdss-dsi-panel-hdr-color-primaries = <15600 16450 34000
	        16000 13250 34500 7500 3000>;
	qcom,mdss-dsi-panel-peak-brightness = <20000000>;
	qcom,mdss-dsi-panel-blackness-level = <1>;
	qcom,is_legacy_panel;
	qcom,apl-enabled;
	qcom,mdss-dsi-panel-APL-THRESHOLD-BL = <15102>;
	qcom,mdss-dsi-panel-APL-FUNC-ID = <0>;
	qcom,mdss-dsi-panel-apl-on-command = [
		39 00 00 00 00 00 03 5F 00 01];
	qcom,mdss-dsi-panel-apl-off-command = [
		39 00 00 00 00 00 03 5F 00 00];
	qcom,partition-refreshrate-enabled;
	qcom,mdss-dsi-panel-boundaryLine-reg-count = <6>;
	//qcom,ulps-enabled;
	qcom,mdss-dsi-hbm-off-command = [
		39 00 00 40 00 00 03 5F 00 00
		39 00 00 00 00 00 03 51 2C 50
	];
	qcom,mdss-dsi-hbm-off-command-state = "dsi_hs_mode";
	qcom,mdss-dsi-hbm-on-command = [
		39 00 00 40 00 00 03 5F 00 01
		39 00 00 00 00 00 03 51 3F FC
	];
	qcom,mdss-dsi-hbm-on-command-state = "dsi_hs_mode";
	qcom,mdss-dsi-display-timings {
		timing@0 { //120
			qcom,framerate-group-no-duplicated;
			qcom,framerate-group-120hz-based;
			qcom,partial-update-enabled = "single_roi";
			qcom,panel-roi-alignment = <1224 160 1224 160 1224 160>;
			qcom,mdss-dsi-panel-clockrate = <1036000000>;
			qcom,display-topology = <2 2 1>;
			qcom,default-topology-index = <0>;
			qcom,mdss-dsi-panel-phy-timings = [00 22 09 09 19 18 09
							09 09 02 04 00 1D 0E];
		};
		timing@1 { //90
			qcom,framerate-group-no-duplicated;
			qcom,framerate-group-90hz-based;
			qcom,partial-update-enabled = "single_roi";
			qcom,panel-roi-alignment = <1224 160 1224 160 1224 160>;
			qcom,mdss-dsi-panel-clockrate = <777000000>;
			qcom,display-topology = <2 2 1>;
			qcom,default-topology-index = <0>;
			qcom,mdss-dsi-panel-phy-timings = [00 1B 07 06 16 21 07
							07 07 02 04 00 17 0C];
		};
		timing@2 { //60
			qcom,framerate-group-no-duplicated;
			qcom,framerate-group-120hz-based;
			qcom,partial-update-enabled = "single_roi";
			qcom,panel-roi-alignment = <1224 160 1224 160 1224 160>;
			qcom,mdss-dsi-panel-clockrate = <518000000>;
			qcom,display-topology = <2 2 1>;
			qcom,default-topology-index = <0>;
			qcom,mdss-dsi-panel-phy-timings = [00 13 05 04 13 1E 05
							05 06 02 04 00 12 0A];
		};
		timing@3 { //30
			qcom,framerate-group-no-duplicated;
			qcom,framerate-group-120hz-based;
			qcom,partial-update-enabled = "single_roi";
			qcom,panel-roi-alignment = <1224 160 1224 160 1224 160>;
			qcom,mdss-dsi-panel-clockrate = <1036000000>;
			qcom,display-topology = <2 2 1>;
			qcom,default-topology-index = <0>;
			qcom,mdss-dsi-panel-phy-timings = [00 22 09 09 19 18 09
							09 09 02 04 00 1D 0E];
		};
		timing@4 { //24
			qcom,framerate-group-no-duplicated;
			qcom,framerate-group-120hz-based;
			qcom,partial-update-enabled = "single_roi";
			qcom,panel-roi-alignment = <1224 160 1224 160 1224 160>;
			qcom,mdss-dsi-panel-clockrate = <1036000000>;
			qcom,display-topology = <2 2 1>;
			qcom,default-topology-index = <0>;
			qcom,mdss-dsi-panel-phy-timings = [00 22 09 09 19 18 09
							09 09 02 04 00 1D 0E];
		};
		timing@5 { //10 independent
			qcom,framerate-group-special-idle-10hz;
			qcom,partial-update-enabled = "single_roi";
			qcom,panel-roi-alignment = <1224 160 1224 160 1224 160>;
			qcom,mdss-dsi-panel-clockrate = <1036000000>;
			qcom,display-topology = <2 2 1>;
			qcom,default-topology-index = <0>;
			qcom,mdss-dsi-panel-phy-timings = [00 22 09 09 19 18 09
							09 09 02 04 00 1D 0E];
		};
		timing@6 { //1 independent
			qcom,framerate-group-special-idle-1hz;
			qcom,partial-update-enabled = "single_roi";
			qcom,panel-roi-alignment = <1224 160 1224 160 1224 160>;
			qcom,mdss-dsi-panel-clockrate = <1036000000>;
			qcom,display-topology = <2 2 1>;
			qcom,default-topology-index = <0>;
			qcom,mdss-dsi-panel-phy-timings = [00 22 09 09 19 18 09
							09 09 02 04 00 1D 0E];
		};
		timing@7 { //165
			qcom,framerate-group-no-duplicated;
			qcom,partial-update-enabled = "single_roi";
			qcom,panel-roi-alignment = <1224 160 1224 160 1224 160>;
			qcom,mdss-dsi-panel-clockrate = <1424000000>;
			qcom,display-topology = <2 2 1>;
			qcom,default-topology-index = <0>;
			qcom,mdss-dsi-panel-phy-timings = [00 2E 0C 0C 1D 1B 0C
							0D 0B 02 04 00 25 11];
		};
		/*timing@8 { //10-120-10 independent
			qcom,framerate-group-partition-refreshrate;
			qcom,partial-update-enabled = "single_roi";
			qcom,panel-roi-alignment = <1224 160 1224 160 1224 160>;
			qcom,mdss-dsi-panel-clockrate = <1036000000>;
			qcom,display-topology = <2 2 1>;
			qcom,default-topology-index = <0>;
			qcom,mdss-dsi-panel-phy-timings = [00 22 09 09 19 18 09
							09 09 02 04 00 1D 0E];
		};*/
		timing@8 { //10-60-10 independent
			qcom,framerate-group-partition-refreshrate;
			qcom,partial-update-enabled = "single_roi";
			qcom,panel-roi-alignment = <1224 160 1224 160 1224 160>;
			qcom,mdss-dsi-panel-clockrate = <1036000000>;
			qcom,display-topology = <2 2 1>;
			qcom,default-topology-index = <0>;
			qcom,mdss-dsi-panel-phy-timings = [00 22 09 09 19 18 09
							09 09 02 04 00 1D 0E];
		};
	};
};

&mot_csot_nt37707A_697_1224x2992_dsc_cmd_v1 {
	qcom,dsi-select-clocks = "pll_byte_clk0", "pll_dsi_clk0";
	qcom,panel-supply-entries = <&dsi_panel_pwr_supply_main>;
	qcom,mdss-dsi-no-panel-on-read-support;
	qcom,mdss-dsi-bl-pmic-control-type = "bl_ctrl_dcs";
	qcom,mdss-dsi-bl-min-level = <420>;
	qcom,mdss-dsi-bl-max-level = <15584>;
	qcom,mdss-dsi-bl-default-level = <8190>;
	qcom,mdss-brightness-max-level = <15584>;
	qcom,platform-reset-gpio = <&tlmm 98 0>;
	qcom,platform-vdd-enable-gpio = <&tlmm 111 0>;
	qcom,bl-dsc-cmd-state = "dsi_hs_mode";
	qcom,mdss-dsi-bl-inverted-dbv;
	qcom,mdss-dsi-bl-is-exponent;

	qcom,mdss-dsi-panel-status-check-mode = "reg_read";
	qcom,mdss-dsi-panel-status-command = [06 01 00 01 00 00 01 0a];
	qcom,mdss-dsi-panel-status-command-state = "dsi_lp_mode";
	qcom,mdss-dsi-panel-status-value = <0x9c>;
	qcom,mdss-dsi-panel-status-read-length = <1>;
	qcom,esd-check-enabled;
	qcom,cellid-read-enabled;
	qcom,mdss-dsi-panel-cellid-read-length = <36>;
	qcom,mdss-dsi-panel-cellid-offset = <13>;
	qcom,mdss-dsi-panel-cellid-command = [
		06 01 00 01 00 00 01 AC];

	qcom,mdss-dsi-panel-hdr-enabled;
	qcom,mdss-dsi-panel-hdr-color-primaries = <15600 16450 34000
	        16000 13250 34500 7500 3000>;
	qcom,mdss-dsi-panel-peak-brightness = <20000000>;
	qcom,mdss-dsi-panel-blackness-level = <1>;

	qcom,apl-enabled;
	qcom,mdss-dsi-panel-APL-THRESHOLD-BL = <15102>;
	qcom,mdss-dsi-panel-APL-FUNC-ID = <0>;
	qcom,mdss-dsi-panel-apl-on-command = [
		39 00 00 00 00 00 02 6F 07
		39 00 00 00 00 00 02 51 80];
	qcom,mdss-dsi-panel-apl-off-command = [
		39 00 00 00 00 00 02 6F 07
		39 00 00 00 00 00 02 51 00];
	qcom,partition-refreshrate-enabled;
	qcom,mdss-dsi-panel-boundaryLine-reg-count = <9>;
	//qcom,ulps-enabled;
	qcom,mdss-dsi-hbm-off-command = [
		39 00 00 40 00 00 02 6F 07
		39 00 00 40 00 00 02 51 00
		39 00 00 00 00 00 03 51 2C 50
	];
	qcom,mdss-dsi-hbm-off-command-state = "dsi_hs_mode";
	qcom,mdss-dsi-hbm-on-command = [
		39 00 00 40 00 00 02 6F 07
		39 00 00 40 00 00 02 51 80
		39 00 00 00 00 00 03 51 3F FC
	];
	qcom,mdss-dsi-hbm-on-command-state = "dsi_hs_mode";
	qcom,mdss-dsi-display-timings {
		timing@0 { //120
			qcom,framerate-group-no-duplicated;
			qcom,framerate-group-120hz-based;
			qcom,partial-update-enabled = "single_roi";
			qcom,panel-roi-alignment = <1224 160 1224 160 1224 160>;
			qcom,mdss-dsi-panel-clockrate = <1036000000>;
			qcom,display-topology = <2 2 1>;
			qcom,default-topology-index = <0>;
			qcom,mdss-dsi-panel-phy-timings = [00 22 09 09 19 18 09
							09 09 02 04 00 1D 0E];
		};
		timing@1 { //90
			qcom,framerate-group-no-duplicated;
			qcom,framerate-group-90hz-based;
			qcom,partial-update-enabled = "single_roi";
			qcom,panel-roi-alignment = <1224 160 1224 160 1224 160>;
			qcom,mdss-dsi-panel-clockrate = <777000000>;
			qcom,display-topology = <2 2 1>;
			qcom,default-topology-index = <0>;
			qcom,mdss-dsi-panel-phy-timings = [00 1B 07 06 16 21 07
							07 07 02 04 00 17 0C];
		};
		timing@2 { //60
			qcom,framerate-group-no-duplicated;
			qcom,framerate-group-120hz-based;
			qcom,partial-update-enabled = "single_roi";
			qcom,panel-roi-alignment = <1224 160 1224 160 1224 160>;
			qcom,mdss-dsi-panel-clockrate = <518000000>;
			qcom,display-topology = <2 2 1>;
			qcom,default-topology-index = <0>;
			qcom,mdss-dsi-panel-phy-timings = [00 13 05 04 13 1E 05
							05 06 02 04 00 12 0A];
		};
		timing@3 { //30
			qcom,framerate-group-no-duplicated;
			qcom,framerate-group-120hz-based;
			qcom,partial-update-enabled = "single_roi";
			qcom,panel-roi-alignment = <1224 160 1224 160 1224 160>;
			qcom,mdss-dsi-panel-clockrate = <1036000000>;
			qcom,display-topology = <2 2 1>;
			qcom,default-topology-index = <0>;
			qcom,mdss-dsi-panel-phy-timings = [00 22 09 09 19 18 09
							09 09 02 04 00 1D 0E];
		};
		timing@4 { //24
			qcom,framerate-group-no-duplicated;
			qcom,framerate-group-120hz-based;
			qcom,partial-update-enabled = "single_roi";
			qcom,panel-roi-alignment = <1224 160 1224 160 1224 160>;
			qcom,mdss-dsi-panel-clockrate = <1036000000>;
			qcom,display-topology = <2 2 1>;
			qcom,default-topology-index = <0>;
			qcom,mdss-dsi-panel-phy-timings = [00 22 09 09 19 18 09
							09 09 02 04 00 1D 0E];
		};
		timing@5 { //10 independent
			qcom,framerate-group-special-idle-10hz;
			qcom,partial-update-enabled = "single_roi";
			qcom,panel-roi-alignment = <1224 160 1224 160 1224 160>;
			qcom,mdss-dsi-panel-clockrate = <1036000000>;
			qcom,display-topology = <2 2 1>;
			qcom,default-topology-index = <0>;
			qcom,mdss-dsi-panel-phy-timings = [00 22 09 09 19 18 09
							09 09 02 04 00 1D 0E];
		};
		timing@6 { //1 independent
			qcom,framerate-group-special-idle-1hz;
			qcom,partial-update-enabled = "single_roi";
			qcom,panel-roi-alignment = <1224 160 1224 160 1224 160>;
			qcom,mdss-dsi-panel-clockrate = <1036000000>;
			qcom,display-topology = <2 2 1>;
			qcom,default-topology-index = <0>;
			qcom,mdss-dsi-panel-phy-timings = [00 22 09 09 19 18 09
							09 09 02 04 00 1D 0E];
		};
		timing@7 { //165
			qcom,framerate-group-no-duplicated;
			qcom,partial-update-enabled = "single_roi";
			qcom,panel-roi-alignment = <1224 160 1224 160 1224 160>;
			qcom,mdss-dsi-panel-clockrate = <1424000000>;
			qcom,display-topology = <2 2 1>;
			qcom,default-topology-index = <0>;
			qcom,mdss-dsi-panel-phy-timings = [00 2E 0C 0C 1D 1B 0C
							0D 0B 02 04 00 25 11];
		};
		timing@8 { //10-60-10 independent
			qcom,framerate-group-partition-refreshrate;
			qcom,partial-update-enabled = "single_roi";
			qcom,panel-roi-alignment = <1224 160 1224 160 1224 160>;
			qcom,mdss-dsi-panel-clockrate = <518000000>;
			qcom,display-topology = <2 2 1>;
			qcom,default-topology-index = <0>;
			qcom,mdss-dsi-panel-phy-timings = [00 13 05 04 13 1E 05
							05 06 02 04 00 12 0A];
		};
	};
};

&mot_csot_nt37707A_697_1224x2992_dsc_cmd_v2 {
	qcom,dsi-select-clocks = "pll_byte_clk0", "pll_dsi_clk0";
	qcom,panel-supply-entries = <&dsi_panel_pwr_supply_main>;
	qcom,mdss-dsi-no-panel-on-read-support;
	qcom,mdss-dsi-bl-pmic-control-type = "bl_ctrl_dcs";
	qcom,mdss-dsi-bl-min-level = <420>;
	qcom,mdss-dsi-bl-max-level = <15584>;
	qcom,mdss-dsi-bl-default-level = <8190>;
	qcom,mdss-brightness-max-level = <15584>;
	qcom,platform-reset-gpio = <&tlmm 98 0>;
	qcom,platform-vdd-enable-gpio = <&tlmm 111 0>;
	qcom,bl-dsc-cmd-state = "dsi_hs_mode";
	qcom,mdss-dsi-bl-inverted-dbv;
	qcom,mdss-dsi-bl-is-exponent;

	qcom,mdss-dsi-panel-status-check-mode = "reg_read";
	qcom,mdss-dsi-panel-status-command = [06 01 00 01 00 00 01 0a];
	qcom,mdss-dsi-panel-status-command-state = "dsi_lp_mode";
	qcom,mdss-dsi-panel-status-value = <0x9c>;
	qcom,mdss-dsi-panel-status-read-length = <1>;
	qcom,esd-check-enabled;
	qcom,cellid-read-enabled;
	qcom,mdss-dsi-panel-cellid-read-length = <36>;
	qcom,mdss-dsi-panel-cellid-offset = <13>;
	qcom,mdss-dsi-panel-cellid-command = [
		06 01 00 01 00 00 01 AC];

	qcom,mdss-dsi-panel-hdr-enabled;
	qcom,mdss-dsi-panel-hdr-color-primaries = <15600 16450 34000
	        16000 13250 34500 7500 3000>;
	qcom,mdss-dsi-panel-peak-brightness = <20000000>;
	qcom,mdss-dsi-panel-blackness-level = <1>;

	qcom,apl-enabled;
	qcom,mdss-dsi-panel-APL-THRESHOLD-BL = <15102>;
	qcom,mdss-dsi-panel-APL-FUNC-ID = <0>;
	qcom,mdss-dsi-panel-apl-on-command = [
		39 00 00 00 00 00 02 6F 07
		39 00 00 00 00 00 02 51 80];
	qcom,mdss-dsi-panel-apl-off-command = [
		39 00 00 00 00 00 02 6F 07
		39 00 00 00 00 00 02 51 00];
	qcom,partition-refreshrate-enabled;
	qcom,mdss-dsi-panel-boundaryLine-reg-count = <9>;
	//qcom,ulps-enabled;
	qcom,mdss-dsi-hbm-off-command = [
		39 00 00 40 00 00 02 6F 07
		39 00 00 40 00 00 02 51 00
		39 00 00 00 00 00 03 51 2C 50
	];
	qcom,mdss-dsi-hbm-off-command-state = "dsi_hs_mode";
	qcom,mdss-dsi-hbm-on-command = [
		39 00 00 40 00 00 02 6F 07
		39 00 00 40 00 00 02 51 80
		39 00 00 00 00 00 03 51 3F FC
	];
	qcom,mdss-dsi-hbm-on-command-state = "dsi_hs_mode";
	qcom,mdss-dsi-display-timings {
		timing@0 { //120
			qcom,framerate-group-no-duplicated;
			qcom,framerate-group-120hz-based;
			qcom,partial-update-enabled = "single_roi";
			qcom,panel-roi-alignment = <1224 160 1224 160 1224 160>;
			qcom,mdss-dsi-panel-clockrate = <1036000000>;
			qcom,display-topology = <2 2 1>;
			qcom,default-topology-index = <0>;
			qcom,mdss-dsi-panel-phy-timings = [00 22 09 09 19 18 09
							09 09 02 04 00 1D 0E];
		};
		timing@1 { //90
			qcom,framerate-group-no-duplicated;
			qcom,framerate-group-90hz-based;
			qcom,partial-update-enabled = "single_roi";
			qcom,panel-roi-alignment = <1224 160 1224 160 1224 160>;
			qcom,mdss-dsi-panel-clockrate = <777000000>;
			qcom,display-topology = <2 2 1>;
			qcom,default-topology-index = <0>;
			qcom,mdss-dsi-panel-phy-timings = [00 1B 07 06 16 21 07
							07 07 02 04 00 17 0C];
		};
		timing@2 { //60
			qcom,framerate-group-no-duplicated;
			qcom,framerate-group-120hz-based;
			qcom,partial-update-enabled = "single_roi";
			qcom,panel-roi-alignment = <1224 160 1224 160 1224 160>;
			qcom,mdss-dsi-panel-clockrate = <518000000>;
			qcom,display-topology = <2 2 1>;
			qcom,default-topology-index = <0>;
			qcom,mdss-dsi-panel-phy-timings = [00 13 05 04 13 1E 05
							05 06 02 04 00 12 0A];
		};
		timing@3 { //30
			qcom,framerate-group-no-duplicated;
			qcom,framerate-group-120hz-based;
			qcom,partial-update-enabled = "single_roi";
			qcom,panel-roi-alignment = <1224 160 1224 160 1224 160>;
			qcom,mdss-dsi-panel-clockrate = <1036000000>;
			qcom,display-topology = <2 2 1>;
			qcom,default-topology-index = <0>;
			qcom,mdss-dsi-panel-phy-timings = [00 22 09 09 19 18 09
							09 09 02 04 00 1D 0E];
		};
		timing@4 { //24
			qcom,framerate-group-no-duplicated;
			qcom,framerate-group-120hz-based;
			qcom,partial-update-enabled = "single_roi";
			qcom,panel-roi-alignment = <1224 160 1224 160 1224 160>;
			qcom,mdss-dsi-panel-clockrate = <1036000000>;
			qcom,display-topology = <2 2 1>;
			qcom,default-topology-index = <0>;
			qcom,mdss-dsi-panel-phy-timings = [00 22 09 09 19 18 09
							09 09 02 04 00 1D 0E];
		};
		timing@5 { //10 independent
			qcom,framerate-group-special-idle-10hz;
			qcom,partial-update-enabled = "single_roi";
			qcom,panel-roi-alignment = <1224 160 1224 160 1224 160>;
			qcom,mdss-dsi-panel-clockrate = <1036000000>;
			qcom,display-topology = <2 2 1>;
			qcom,default-topology-index = <0>;
			qcom,mdss-dsi-panel-phy-timings = [00 22 09 09 19 18 09
							09 09 02 04 00 1D 0E];
		};
		timing@6 { //1 independent
			qcom,framerate-group-special-idle-1hz;
			qcom,partial-update-enabled = "single_roi";
			qcom,panel-roi-alignment = <1224 160 1224 160 1224 160>;
			qcom,mdss-dsi-panel-clockrate = <1036000000>;
			qcom,display-topology = <2 2 1>;
			qcom,default-topology-index = <0>;
			qcom,mdss-dsi-panel-phy-timings = [00 22 09 09 19 18 09
							09 09 02 04 00 1D 0E];
		};
		timing@7 { //165
			qcom,framerate-group-no-duplicated;
			qcom,partial-update-enabled = "single_roi";
			qcom,panel-roi-alignment = <1224 160 1224 160 1224 160>;
			qcom,mdss-dsi-panel-clockrate = <1424000000>;
			qcom,display-topology = <2 2 1>;
			qcom,default-topology-index = <0>;
			qcom,mdss-dsi-panel-phy-timings = [00 2E 0C 0C 1D 1B 0C
							0D 0B 02 04 00 25 11];
		};
		timing@8 { //10-60-10 independent
			qcom,framerate-group-partition-refreshrate;
			qcom,partial-update-enabled = "single_roi";
			qcom,panel-roi-alignment = <1224 160 1224 160 1224 160>;
			qcom,mdss-dsi-panel-clockrate = <518000000>;
			qcom,display-topology = <2 2 1>;
			qcom,default-topology-index = <0>;
			qcom,mdss-dsi-panel-phy-timings = [00 13 05 04 13 1E 05
							05 06 02 04 00 12 0A];
		};
	};
};

&mot_csot_nt37707_1080x1272_dsc_cmd_cli_v2 {
	qcom,dsi-select-sec-clocks = "pll_byte_clk1", "pll_dsi_clk1";

	qcom,panel-supply-entries = <&dsi_panel_pwr_supply_main>;
	qcom,panel-sec-supply-entries = <&dsi_panel_pwr_supply_sec>;
	qcom,mdss-dsi-bl-pmic-control-type = "bl_ctrl_dcs";
	qcom,mdss-dsi-sec-bl-pmic-control-type = "bl_ctrl_dcs";
	qcom,mdss-dsi-bl-min-level = <420>;
	qcom,mdss-dsi-bl-max-level = <15584>;
	qcom,mdss-dsi-bl-default-level = <8190>;
	qcom,mdss-brightness-max-level = <15584>;
	qcom,platform-sec-reset-gpio = <&tlmm 73 0>;
	/* qcom,platform-sec-vio-enable-gpio = <&tlmm 97 0>; */
	qcom,platform-sec-vdd-enable-gpio = <&tlmm 60 0>;
	qcom,mdss-dsi-panel-orientation = "180";
	qcom,mdss-dsi-panel-status-check-mode = "reg_read";
	qcom,mdss-dsi-panel-status-command = [06 01 00 01 00 00 01 0a];
	qcom,mdss-dsi-panel-status-command-state = "dsi_lp_mode";
	qcom,mdss-dsi-panel-status-value = <0x9c>;
	qcom,mdss-dsi-panel-status-read-length = <1>;
	qcom,esd-check-enabled;
	qcom,mdss-dsi-bl-inverted-dbv;
	qcom,mdss-dsi-bl-is-exponent;

	qcom,mdss-dsi-no-panel-on-read-support;
	qcom,cellid-read-enabled;
	qcom,mdss-dsi-panel-cellid-read-length = <36>;
	qcom,mdss-dsi-panel-cellid-offset = <13>;
	qcom,mdss-dsi-panel-cellid-command = [
		06 01 00 01 00 00 01 AC];

	qcom,mdss-dsi-panel-hdr-enabled;
	qcom,mdss-dsi-panel-hdr-color-primaries = <15600 16450 34000
	        16000 13250 34500 7500 3000>;
	qcom,mdss-dsi-panel-peak-brightness = <20000000>;
	qcom,mdss-dsi-panel-blackness-level = <1>;

	qcom,apl-enabled;
	qcom,mdss-dsi-panel-APL-THRESHOLD-BL = <15102>;
	qcom,mdss-dsi-panel-APL-FUNC-ID = <0>;
	qcom,mdss-dsi-panel-apl-on-command = [
		39 00 00 00 00 00 03 5F 00 01];
	qcom,mdss-dsi-panel-apl-off-command = [
		39 00 00 00 00 00 03 5F 00 00];

	qcom,mdss-dsi-panel-AOD-config-enabled;
	qcom,mdss-dsi-panel-AOD-THRESHOLD-BL = <4272>;

	qcom,mdss-dsi-hbm-off-command = [
		39 00 00 40 00 00 03 5F 00 00
		39 00 00 00 00 00 03 51 2C 50
	];
	qcom,mdss-dsi-hbm-off-command-state = "dsi_hs_mode";
	qcom,mdss-dsi-hbm-on-command = [
		39 00 00 40 00 00 03 5F 00 01
		39 00 00 00 00 00 03 51 3F FC
	];
	qcom,mdss-dsi-hbm-on-command-state = "dsi_hs_mode";

	qcom,mdss-dsi-display-timings {
		timing@0{//120hz
			qcom,framerate-group-no-duplicated;
			qcom,framerate-group-120hz-based;
		        qcom,mdss-dsi-panel-clockrate = <667500000>;
			qcom,display-topology = <2 2 1>;
			qcom,default-topology-index = <0>;
			qcom,mdss-dsi-panel-phy-timings = [00 10 04 04 12 11 04
							04 03 02 04 00 0E 09];
		};
		timing@1{//165hz
			qcom,framerate-group-no-duplicated;
			qcom,mdss-dsi-panel-clockrate = <667500000>;
			qcom,display-topology = <2 2 1>;
			qcom,default-topology-index = <0>;
			qcom,mdss-dsi-panel-phy-timings = [00 15 05 05 14 13 05
							05 06 02 04 00 13 0A];
		};
		timing@2{//90hz
			qcom,framerate-group-no-duplicated;
			qcom,framerate-group-90hz-based;
			qcom,mdss-dsi-panel-clockrate = <667500000>;
			qcom,display-topology = <2 2 1>;
			qcom,default-topology-index = <0>;
			qcom,mdss-dsi-panel-phy-timings = [00 10 04 04 12 11 04
							04 03 02 04 00 0E 09];
		};
		timing@3{//60hz
			qcom,framerate-group-no-duplicated;
			qcom,framerate-group-120hz-based;
			qcom,mdss-dsi-panel-clockrate = <667500000>;
			qcom,display-topology = <2 2 1>;
			qcom,default-topology-index = <0>;
			qcom,mdss-dsi-panel-phy-timings = [00 10 04 04 12 11 04
							04 03 02 04 00 0E 09];
		};
		timing@4{//30hz
			qcom,framerate-group-no-duplicated;
			qcom,framerate-group-120hz-based;
			qcom,framerate-group-90hz-based;
			qcom,mdss-dsi-panel-clockrate = <667500000>;
			qcom,display-topology = <2 2 1>;
			qcom,default-topology-index = <0>;
			qcom,mdss-dsi-panel-phy-timings = [00 10 04 04 12 11 04
							04 03 02 04 00 0E 09];
		};
		timing@5{//24hz
			qcom,framerate-group-no-duplicated;
			qcom,framerate-group-120hz-based;
			qcom,mdss-dsi-panel-clockrate = <667500000>;
			qcom,display-topology = <2 2 1>;
			qcom,default-topology-index = <0>;
			qcom,mdss-dsi-panel-phy-timings = [00 10 04 04 12 11 04
							04 03 02 04 00 0E 09];
		};
		timing@6{//10hz
			qcom,framerate-group-special-idle-10hz;
			qcom,mdss-dsi-panel-clockrate = <667500000>;
			qcom,display-topology = <2 2 1>;
			qcom,default-topology-index = <0>;
			qcom,mdss-dsi-panel-phy-timings = [00 10 04 04 12 11 04
							04 03 02 04 00 0E 09];
		};
		timing@7{//1hz
			qcom,framerate-group-special-idle-1hz;
			qcom,mdss-dsi-panel-clockrate = <667500000>;
			qcom,display-topology = <2 2 1>;
			qcom,default-topology-index = <0>;
			qcom,mdss-dsi-panel-phy-timings = [00 10 04 04 12 11 04
							04 03 02 04 00 0E 09];
		};
	};
};

&mot_csot_nt37707_1080x1272_dsc_cmd_cli_v3 {
	qcom,dsi-select-sec-clocks = "pll_byte_clk1", "pll_dsi_clk1";

	qcom,panel-supply-entries = <&dsi_panel_pwr_supply_main>;
	qcom,panel-sec-supply-entries = <&dsi_panel_pwr_supply_sec>;
	qcom,mdss-dsi-bl-pmic-control-type = "bl_ctrl_dcs";
	qcom,mdss-dsi-sec-bl-pmic-control-type = "bl_ctrl_dcs";
	qcom,mdss-dsi-bl-min-level = <420>;
	qcom,mdss-dsi-bl-max-level = <15584>;
	qcom,mdss-dsi-bl-default-level = <8190>;
	qcom,mdss-brightness-max-level = <15584>;
	qcom,platform-sec-reset-gpio = <&tlmm 73 0>;
	/* qcom,platform-sec-vio-enable-gpio = <&tlmm 97 0>; */
	qcom,platform-sec-vdd-enable-gpio = <&tlmm 60 0>;
	qcom,mdss-dsi-panel-orientation = "180";
	qcom,mdss-dsi-panel-status-check-mode = "reg_read";
	qcom,mdss-dsi-panel-status-command = [06 01 00 01 00 00 01 0a];
	qcom,mdss-dsi-panel-status-command-state = "dsi_lp_mode";
	qcom,mdss-dsi-panel-status-value = <0x9c>;
	qcom,mdss-dsi-panel-status-read-length = <1>;
	qcom,esd-check-enabled;
	qcom,mdss-dsi-bl-inverted-dbv;
	qcom,mdss-dsi-bl-is-exponent;

	qcom,mdss-dsi-no-panel-on-read-support;
	qcom,cellid-read-enabled;
	qcom,mdss-dsi-panel-cellid-read-length = <36>;
	qcom,mdss-dsi-panel-cellid-offset = <13>;
	qcom,mdss-dsi-panel-cellid-command = [
		06 01 00 01 00 00 01 AC];

	qcom,mdss-dsi-panel-hdr-enabled;
	qcom,mdss-dsi-panel-hdr-color-primaries = <15600 16450 34000
	        16000 13250 34500 7500 3000>;
	qcom,mdss-dsi-panel-peak-brightness = <20000000>;
	qcom,mdss-dsi-panel-blackness-level = <1>;

	qcom,apl-enabled;
	qcom,mdss-dsi-panel-APL-THRESHOLD-BL = <15102>;
	qcom,mdss-dsi-panel-APL-FUNC-ID = <0>;
	qcom,mdss-dsi-panel-apl-on-command = [
		39 00 00 00 00 00 03 5F 00 01];
	qcom,mdss-dsi-panel-apl-off-command = [
		39 00 00 00 00 00 03 5F 00 00];

	qcom,mdss-dsi-panel-AOD-config-enabled;
	qcom,mdss-dsi-panel-AOD-THRESHOLD-BL = <4272>;

	qcom,mdss-dsi-hbm-off-command = [
		39 00 00 40 00 00 03 5F 00 00
		39 00 00 00 00 00 03 51 2C 50
	];
	qcom,mdss-dsi-hbm-off-command-state = "dsi_hs_mode";
	qcom,mdss-dsi-hbm-on-command = [
		39 00 00 40 00 00 03 5F 00 01
		39 00 00 00 00 00 03 51 3F FC
	];
	qcom,mdss-dsi-hbm-on-command-state = "dsi_hs_mode";

	qcom,mdss-dsi-display-timings {
		timing@0{//120hz
			qcom,framerate-group-no-duplicated;
			qcom,framerate-group-120hz-based;
		        qcom,mdss-dsi-panel-clockrate = <667500000>;
			qcom,display-topology = <2 2 1>;
			qcom,default-topology-index = <0>;
			qcom,mdss-dsi-panel-phy-timings = [00 10 04 04 12 11 04
							04 03 02 04 00 0E 09];
		};
		timing@1{//165hz
			qcom,framerate-group-no-duplicated;
			qcom,mdss-dsi-panel-clockrate = <667500000>;
			qcom,display-topology = <2 2 1>;
			qcom,default-topology-index = <0>;
			qcom,mdss-dsi-panel-phy-timings = [00 15 05 05 14 13 05
							05 06 02 04 00 13 0A];
		};
		timing@2{//90hz
			qcom,framerate-group-no-duplicated;
			qcom,framerate-group-90hz-based;
			qcom,mdss-dsi-panel-clockrate = <667500000>;
			qcom,display-topology = <2 2 1>;
			qcom,default-topology-index = <0>;
			qcom,mdss-dsi-panel-phy-timings = [00 10 04 04 12 11 04
							04 03 02 04 00 0E 09];
		};
		timing@3{//60hz
			qcom,framerate-group-no-duplicated;
			qcom,framerate-group-120hz-based;
			qcom,mdss-dsi-panel-clockrate = <667500000>;
			qcom,display-topology = <2 2 1>;
			qcom,default-topology-index = <0>;
			qcom,mdss-dsi-panel-phy-timings = [00 10 04 04 12 11 04
							04 03 02 04 00 0E 09];
		};
		timing@4{//30hz
			qcom,framerate-group-no-duplicated;
			qcom,framerate-group-120hz-based;
			qcom,framerate-group-90hz-based;
			qcom,mdss-dsi-panel-clockrate = <667500000>;
			qcom,display-topology = <2 2 1>;
			qcom,default-topology-index = <0>;
			qcom,mdss-dsi-panel-phy-timings = [00 10 04 04 12 11 04
							04 03 02 04 00 0E 09];
		};
		timing@5{//24hz
			qcom,framerate-group-no-duplicated;
			qcom,framerate-group-120hz-based;
			qcom,mdss-dsi-panel-clockrate = <667500000>;
			qcom,display-topology = <2 2 1>;
			qcom,default-topology-index = <0>;
			qcom,mdss-dsi-panel-phy-timings = [00 10 04 04 12 11 04
							04 03 02 04 00 0E 09];
		};
		timing@6{//10hz
			qcom,framerate-group-special-idle-10hz;
			qcom,mdss-dsi-panel-clockrate = <667500000>;
			qcom,display-topology = <2 2 1>;
			qcom,default-topology-index = <0>;
			qcom,mdss-dsi-panel-phy-timings = [00 10 04 04 12 11 04
							04 03 02 04 00 0E 09];
		};
		timing@7{//1hz
			qcom,framerate-group-special-idle-1hz;
			qcom,mdss-dsi-panel-clockrate = <667500000>;
			qcom,display-topology = <2 2 1>;
			qcom,default-topology-index = <0>;
			qcom,mdss-dsi-panel-phy-timings = [00 10 04 04 12 11 04
							04 03 02 04 00 0E 09];
		};
	};
};

&mot_csot_nt37707_1080x1272_dsc_cmd_cli_v4 {
	qcom,dsi-select-sec-clocks = "pll_byte_clk1", "pll_dsi_clk1";

	qcom,panel-supply-entries = <&dsi_panel_pwr_supply_main>;
	qcom,panel-sec-supply-entries = <&dsi_panel_pwr_supply_sec>;
	qcom,mdss-dsi-bl-pmic-control-type = "bl_ctrl_dcs";
	qcom,mdss-dsi-sec-bl-pmic-control-type = "bl_ctrl_dcs";
	qcom,mdss-dsi-bl-min-level = <420>;
	qcom,mdss-dsi-bl-max-level = <15584>;
	qcom,mdss-dsi-bl-default-level = <8190>;
	qcom,mdss-brightness-max-level = <15584>;
	qcom,platform-sec-reset-gpio = <&tlmm 73 0>;
	/* qcom,platform-sec-vio-enable-gpio = <&tlmm 97 0>; */
	qcom,platform-sec-vdd-enable-gpio = <&tlmm 60 0>;
	qcom,mdss-dsi-panel-orientation = "180";
	qcom,mdss-dsi-panel-status-check-mode = "reg_read";
	qcom,mdss-dsi-panel-status-command = [06 01 00 01 00 00 01 0a];
	qcom,mdss-dsi-panel-status-command-state = "dsi_lp_mode";
	qcom,mdss-dsi-panel-status-value = <0x9c>;
	qcom,mdss-dsi-panel-status-read-length = <1>;
	qcom,esd-check-enabled;
	qcom,mdss-dsi-bl-inverted-dbv;
	qcom,mdss-dsi-bl-is-exponent;

	qcom,mdss-dsi-no-panel-on-read-support;
	qcom,cellid-read-enabled;
	qcom,mdss-dsi-panel-cellid-read-length = <36>;
	qcom,mdss-dsi-panel-cellid-offset = <13>;
	qcom,mdss-dsi-panel-cellid-command = [
		06 01 00 01 00 00 01 AC];

	qcom,mdss-dsi-panel-hdr-enabled;
	qcom,mdss-dsi-panel-hdr-color-primaries = <15600 16450 34000
	        16000 13250 34500 7500 3000>;
	qcom,mdss-dsi-panel-peak-brightness = <20000000>;
	qcom,mdss-dsi-panel-blackness-level = <1>;

	qcom,apl-enabled;
	qcom,mdss-dsi-panel-APL-THRESHOLD-BL = <15102>;
	qcom,mdss-dsi-panel-APL-FUNC-ID = <0>;
	qcom,mdss-dsi-panel-apl-on-command = [
		39 00 00 00 00 00 03 5F 00 01];
	qcom,mdss-dsi-panel-apl-off-command = [
		39 00 00 00 00 00 03 5F 00 00];

	qcom,mdss-dsi-panel-AOD-config-enabled;
	qcom,mdss-dsi-panel-AOD-THRESHOLD-BL = <4272>;

	qcom,mdss-dsi-hbm-off-command = [
		39 00 00 40 00 00 03 5F 00 00
		39 00 00 00 00 00 03 51 2C 50
	];
	qcom,mdss-dsi-hbm-off-command-state = "dsi_hs_mode";
	qcom,mdss-dsi-hbm-on-command = [
		39 00 00 40 00 00 03 5F 00 01
		39 00 00 00 00 00 03 51 3F FC
	];
	qcom,mdss-dsi-hbm-on-command-state = "dsi_hs_mode";

	qcom,mdss-dsi-display-timings {
		timing@0{//120hz
			qcom,framerate-group-no-duplicated;
			qcom,framerate-group-120hz-based;
		        qcom,mdss-dsi-panel-clockrate = <667500000>;
			qcom,display-topology = <2 2 1>;
			qcom,default-topology-index = <0>;
			qcom,mdss-dsi-panel-phy-timings = [00 10 04 04 12 11 04
							04 03 02 04 00 0E 09];
		};
		timing@1{//165hz
			qcom,framerate-group-no-duplicated;
			qcom,mdss-dsi-panel-clockrate = <667500000>;
			qcom,display-topology = <2 2 1>;
			qcom,default-topology-index = <0>;
			qcom,mdss-dsi-panel-phy-timings = [00 15 05 05 14 13 05
							05 06 02 04 00 13 0A];
		};
		timing@2{//90hz
			qcom,framerate-group-no-duplicated;
			qcom,framerate-group-90hz-based;
			qcom,mdss-dsi-panel-clockrate = <667500000>;
			qcom,display-topology = <2 2 1>;
			qcom,default-topology-index = <0>;
			qcom,mdss-dsi-panel-phy-timings = [00 10 04 04 12 11 04
							04 03 02 04 00 0E 09];
		};
		timing@3{//60hz
			qcom,framerate-group-no-duplicated;
			qcom,framerate-group-120hz-based;
			qcom,mdss-dsi-panel-clockrate = <667500000>;
			qcom,display-topology = <2 2 1>;
			qcom,default-topology-index = <0>;
			qcom,mdss-dsi-panel-phy-timings = [00 10 04 04 12 11 04
							04 03 02 04 00 0E 09];
		};
		timing@4{//30hz
			qcom,framerate-group-no-duplicated;
			qcom,framerate-group-120hz-based;
			qcom,framerate-group-90hz-based;
			qcom,mdss-dsi-panel-clockrate = <667500000>;
			qcom,display-topology = <2 2 1>;
			qcom,default-topology-index = <0>;
			qcom,mdss-dsi-panel-phy-timings = [00 10 04 04 12 11 04
							04 03 02 04 00 0E 09];
		};
		timing@5{//24hz
			qcom,framerate-group-no-duplicated;
			qcom,framerate-group-120hz-based;
			qcom,mdss-dsi-panel-clockrate = <667500000>;
			qcom,display-topology = <2 2 1>;
			qcom,default-topology-index = <0>;
			qcom,mdss-dsi-panel-phy-timings = [00 10 04 04 12 11 04
							04 03 02 04 00 0E 09];
		};
		timing@6{//10hz
			qcom,framerate-group-special-idle-10hz;
			qcom,mdss-dsi-panel-clockrate = <667500000>;
			qcom,display-topology = <2 2 1>;
			qcom,default-topology-index = <0>;
			qcom,mdss-dsi-panel-phy-timings = [00 10 04 04 12 11 04
							04 03 02 04 00 0E 09];
		};
		timing@7{//1hz
			qcom,framerate-group-special-idle-1hz;
			qcom,mdss-dsi-panel-clockrate = <667500000>;
			qcom,display-topology = <2 2 1>;
			qcom,default-topology-index = <0>;
			qcom,mdss-dsi-panel-phy-timings = [00 10 04 04 12 11 04
							04 03 02 04 00 0E 09];
		};
	};
};

&mot_csot_nt37707_1080x1272_dsc_cmd_cli_v5 {
	qcom,dsi-select-sec-clocks = "pll_byte_clk1", "pll_dsi_clk1";

	qcom,panel-supply-entries = <&dsi_panel_pwr_supply_main>;
	qcom,panel-sec-supply-entries = <&dsi_panel_pwr_supply_sec>;
	qcom,mdss-dsi-bl-pmic-control-type = "bl_ctrl_dcs";
	qcom,mdss-dsi-sec-bl-pmic-control-type = "bl_ctrl_dcs";
	qcom,mdss-dsi-bl-min-level = <420>;
	qcom,mdss-dsi-bl-max-level = <15584>;
	qcom,mdss-dsi-bl-default-level = <8190>;
	qcom,mdss-brightness-max-level = <15584>;
	qcom,platform-sec-reset-gpio = <&tlmm 73 0>;
	/* qcom,platform-sec-vio-enable-gpio = <&tlmm 97 0>; */
	qcom,platform-sec-vdd-enable-gpio = <&tlmm 60 0>;
	qcom,mdss-dsi-panel-orientation = "180";
	qcom,mdss-dsi-panel-status-check-mode = "reg_read";
	qcom,mdss-dsi-panel-status-command = [06 01 00 01 00 00 01 0a];
	qcom,mdss-dsi-panel-status-command-state = "dsi_lp_mode";
	qcom,mdss-dsi-panel-status-value = <0x9c>;
	qcom,mdss-dsi-panel-status-read-length = <1>;
	qcom,esd-check-enabled;
	qcom,mdss-dsi-bl-inverted-dbv;
	qcom,mdss-dsi-bl-is-exponent;

	qcom,mdss-dsi-no-panel-on-read-support;
	qcom,cellid-read-enabled;
	qcom,mdss-dsi-panel-cellid-read-length = <36>;
	qcom,mdss-dsi-panel-cellid-offset = <13>;
	qcom,mdss-dsi-panel-cellid-command = [
		06 01 00 01 00 00 01 AC];

	qcom,mdss-dsi-panel-hdr-enabled;
	qcom,mdss-dsi-panel-hdr-color-primaries = <15600 16450 34000
	        16000 13250 34500 7500 3000>;
	qcom,mdss-dsi-panel-peak-brightness = <20000000>;
	qcom,mdss-dsi-panel-blackness-level = <1>;

	qcom,apl-enabled;
	qcom,mdss-dsi-panel-APL-THRESHOLD-BL = <15102>;
	qcom,mdss-dsi-panel-APL-FUNC-ID = <0>;
	qcom,mdss-dsi-panel-apl-on-command = [
		39 00 00 00 00 00 03 5F 00 01];
	qcom,mdss-dsi-panel-apl-off-command = [
		39 00 00 00 00 00 03 5F 00 00];

	qcom,mdss-dsi-panel-AOD-config-enabled;
	qcom,mdss-dsi-panel-AOD-THRESHOLD-BL = <4272>;

	qcom,mdss-dsi-hbm-off-command = [
		39 00 00 40 00 00 03 5F 00 00
		39 00 00 00 00 00 03 51 2C 50
	];
	qcom,mdss-dsi-hbm-off-command-state = "dsi_hs_mode";
	qcom,mdss-dsi-hbm-on-command = [
		39 00 00 40 00 00 03 5F 00 01
		39 00 00 00 00 00 03 51 3F FC
	];
	qcom,mdss-dsi-hbm-on-command-state = "dsi_hs_mode";

	qcom,mdss-dsi-display-timings {
		timing@0{//120hz
			qcom,framerate-group-no-duplicated;
			qcom,framerate-group-120hz-based;
		        qcom,mdss-dsi-panel-clockrate = <667500000>;
			qcom,display-topology = <2 2 1>;
			qcom,default-topology-index = <0>;
			qcom,mdss-dsi-panel-phy-timings = [00 10 04 04 12 11 04
							04 03 02 04 00 0E 09];
		};
		timing@1{//165hz
			qcom,framerate-group-no-duplicated;
			qcom,mdss-dsi-panel-clockrate = <667500000>;
			qcom,display-topology = <2 2 1>;
			qcom,default-topology-index = <0>;
			qcom,mdss-dsi-panel-phy-timings = [00 15 05 05 14 13 05
							05 06 02 04 00 13 0A];
		};
		timing@2{//90hz
			qcom,framerate-group-no-duplicated;
			qcom,framerate-group-90hz-based;
			qcom,mdss-dsi-panel-clockrate = <667500000>;
			qcom,display-topology = <2 2 1>;
			qcom,default-topology-index = <0>;
			qcom,mdss-dsi-panel-phy-timings = [00 10 04 04 12 11 04
							04 03 02 04 00 0E 09];
		};
		timing@3{//60hz
			qcom,framerate-group-no-duplicated;
			qcom,framerate-group-120hz-based;
			qcom,mdss-dsi-panel-clockrate = <667500000>;
			qcom,display-topology = <2 2 1>;
			qcom,default-topology-index = <0>;
			qcom,mdss-dsi-panel-phy-timings = [00 10 04 04 12 11 04
							04 03 02 04 00 0E 09];
		};
		timing@4{//30hz
			qcom,framerate-group-no-duplicated;
			qcom,framerate-group-120hz-based;
			qcom,framerate-group-90hz-based;
			qcom,mdss-dsi-panel-clockrate = <667500000>;
			qcom,display-topology = <2 2 1>;
			qcom,default-topology-index = <0>;
			qcom,mdss-dsi-panel-phy-timings = [00 10 04 04 12 11 04
							04 03 02 04 00 0E 09];
		};
		timing@5{//24hz
			qcom,framerate-group-no-duplicated;
			qcom,framerate-group-120hz-based;
			qcom,mdss-dsi-panel-clockrate = <667500000>;
			qcom,display-topology = <2 2 1>;
			qcom,default-topology-index = <0>;
			qcom,mdss-dsi-panel-phy-timings = [00 10 04 04 12 11 04
							04 03 02 04 00 0E 09];
		};
		timing@6{//10hz
			qcom,framerate-group-special-idle-10hz;
			qcom,mdss-dsi-panel-clockrate = <667500000>;
			qcom,display-topology = <2 2 1>;
			qcom,default-topology-index = <0>;
			qcom,mdss-dsi-panel-phy-timings = [00 10 04 04 12 11 04
							04 03 02 04 00 0E 09];
		};
		timing@7{//1hz
			qcom,framerate-group-special-idle-1hz;
			qcom,mdss-dsi-panel-clockrate = <667500000>;
			qcom,display-topology = <2 2 1>;
			qcom,default-topology-index = <0>;
			qcom,mdss-dsi-panel-phy-timings = [00 10 04 04 12 11 04
							04 03 02 04 00 0E 09];
		};
	};
};

&mot_dummy_vid_qhd {
       qcom,mdss-dsi-display-timings {
                timing@0{
                       qcom,mdss-dsi-panel-width = <1080>;
                       qcom,mdss-dsi-panel-height = <2400>;
               };
       };
};

&mot_dummy_vid_qhd {
	qcom,platform-reset-gpio = <&tlmm 98 0>;

	qcom,dsi-select-clocks = "pll_byte_clk0", "pll_dsi_clk0";
	qcom,mdss-dsi-display-timings {
		timing@0 {
			qcom,display-topology = <1 0 1>;
			qcom,default-topology-index = <0>;
		};
	};
};

&sde_dsi {
	qcom,dsi-default-panel = <&mot_dummy_vid_qhd>;
};

&qupv3_se4_spi {
	goodix-berlin@0 {
		panel = <&mot_csot_nt37707_667_1080x2640_dsc_cmd_v1
			&mot_csot_nt37707_697_1224x2992_dsc_cmd_v1
			&mot_csot_nt37707_697_1224x2992_dsc_cmd_v2
			&mot_csot_nt37707_697_1224x2992_dsc_cmd_v3
			&mot_csot_nt37707_697_1224x2992_dsc_cmd_v4
			&mot_csot_nt37707_697_1224x2992_dsc_cmd_v5
			&mot_csot_nt37707A_697_1224x2992_dsc_cmd_v1
			&mot_csot_nt37707A_697_1224x2992_dsc_cmd_v2
			&mot_csot_nt37707_697_1224x2992_dsc_cmd_c9_v1>;
	};
};

&qupv3_se15_spi {
	focaltech@0 {
		panel = <&mot_csot_nt37707_1080x1272_dsc_cmd_cli_v2
			&mot_csot_nt37707_1080x1272_dsc_cmd_cli_v3
			&mot_csot_nt37707_1080x1272_dsc_cmd_cli_v4
			&mot_csot_nt37707_1080x1272_dsc_cmd_cli_v5>;
	};
};

